VERSION ""

CM_ "AUTOGENERATED FILE, DO NOT EDIT";

CM_ "tesla_radar_continental.dbc starts here";

NS_ :

BS_:

BU_:  Autopilot Radar Diag

BO_ 1025 RadarStatus: 8 Radar
   SG_ carparkDetected : 29|1@1+ (1,0) [0|1] "" Autopilot
   SG_ decreaseBlockage : 25|1@1+ (1,0) [0|1] "" Autopilot
   SG_ horizontMisalignment : 8|12@1+ (0.00012207,-0.25) [-0.25|0.249878] "rad" Autopilot
   SG_ increaseBlockage : 24|1@1+ (1,0) [0|1] "" Autopilot
   SG_ lowPowerMode : 20|2@1+ (1,0) [0|3] "" Autopilot
   SG_ powerOnSelfTest : 22|1@1+ (1,0) [0|1] "" Autopilot
   SG_ sensorBlocked : 26|1@1+ (1,0) [0|1] "" Autopilot
   SG_ sensorInfoConsistBit : 30|1@1+ (1,0) [0|1] "" Autopilot
   SG_ sensorReplace : 31|1@1+ (1,0) [0|1] "" Autopilot
   SG_ shortTermUnavailable : 23|1@1+ (1,0) [0|1] "" Autopilot
   SG_ tunnelDetected : 28|1@1+ (1,0) [0|1] "" Autopilot
   SG_ vehDynamicsError : 27|1@1+ (1,0) [0|1] "" Autopilot
   SG_ verticalMisalignment : 0|8@1+ (0.00195313,-0.25) [-0.25|0.248047] "rad" Autopilot

BO_ 1617 Radar_udsResponse: 8 Radar
   SG_ Radar_udsResponseData : 7|64@0+ (1,0) [0|1.84467e+19] "" Diag

BO_ 1601 UDS_radcRequest: 8 Diag
   SG_ UDS_radcRequestData : 7|64@0+ (1,0) [0|1.84467e+19] "" Radar

BO_ 1040 RadarPoint0_A: 8 Radar
 SG_ LongDist : 0|12@1+ (0.0625,0) [0|255.9] "meters"  Autopilot
 SG_ LongSpeed : 12|12@1+ (0.0625,-128) [-128|128] "meters/sec"  Autopilot
 SG_ LatDist : 24|11@1+ (0.125,-128) [-128|128] "meters"  Autopilot
 SG_ ProbExist : 35|5@1+ (3.125,0) [0|96.875] "%"  Autopilot
 SG_ LongAccel : 40|10@1+ (0.03125,-16) [-16|16] "meters/sec/sec"  Autopilot
 SG_ ProbObstacle : 50|5@1+ (3.125,0) [0|96.875] "%"  Autopilot
 SG_ Valid : 55|1@1+ (1,0) [0|1] ""  Autopilot
 SG_ ProbNonObstacle : 56|5@1+ (3.125,0) [0|96.875] "%"  Autopilot
 SG_ Meas : 61|1@1+ (1,0) [0|1] ""  Autopilot
 SG_ Tracked : 62|1@1+ (1,0) [0|1] ""  Autopilot
 SG_ Index : 63|1@1+ (1,0) [0|1] ""  Autopilot

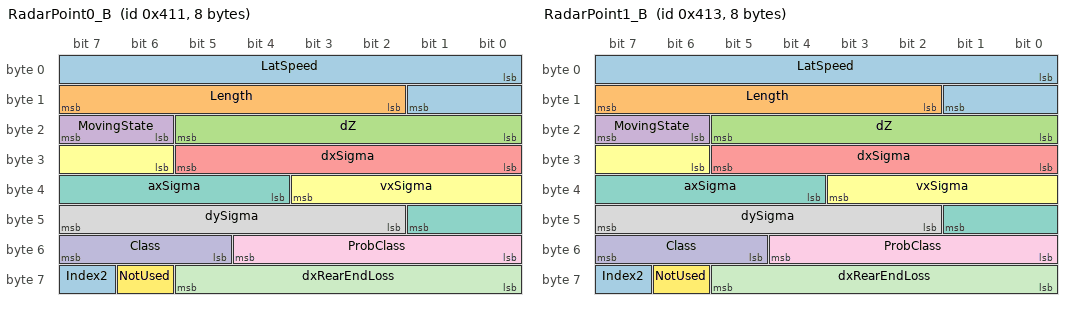
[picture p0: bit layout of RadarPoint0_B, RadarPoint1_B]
BO_ 1041 RadarPoint0_B: 8 Radar
 SG_ LatSpeed : 0|10@1+ (0.125,-64) [-64|64] "meters/sec"  Autopilot
 SG_ Length : 10|6@1+ (0.125,0) [0|7.875] "m"  Autopilot
 SG_ dZ : 16|6@1+ (0.25,-5) [-5|10.75] "m"  Autopilot
 SG_ MovingState : 22|2@1+ (1,0) [0|3] ""  Autopilot
 SG_ dxSigma : 24|6@1+ (1,0) [0|63] ""  Autopilot
 SG_ vxSigma : 30|6@1+ (1,0) [0|63] ""  Autopilot
 SG_ axSigma : 36|6@1+ (1,0) [0|63] ""  Autopilot
 SG_ dySigma : 42|6@1+ (1,0) [0|63] ""  Autopilot
 SG_ ProbClass : 48|5@1+ (3.125,0) [0|96.875] "%"  Autopilot
 SG_ Class : 53|3@1+ (1,0) [0|7] ""  Autopilot
 SG_ dxRearEndLoss : 56|6@1+ (1,0) [0|63] ""  Autopilot
 SG_ NotUsed : 62|1@1+ (1,0) [0|1] ""  Autopilot
 SG_ Index2 : 63|1@1+ (1,0) [0|1] ""  Autopilot

BO_ 1042 RadarPoint1_A: 8 Radar
 SG_ LongDist : 0|12@1+ (0.0625,0) [0|255.9] "meters"  Autopilot
 SG_ LongSpeed : 12|12@1+ (0.0625,-128) [-128|128] "meters/sec"  Autopilot
 SG_ LatDist : 24|11@1+ (0.125,-128) [-128|128] "meters"  Autopilot
 SG_ ProbExist : 35|5@1+ (3.125,0) [0|96.875] "%"  Autopilot
 SG_ LongAccel : 40|10@1+ (0.03125,-16) [-16|16] "meters/sec/sec"  Autopilot
 SG_ ProbObstacle : 50|5@1+ (3.125,0) [0|96.875] "%"  Autopilot
 SG_ Valid : 55|1@1+ (1,0) [0|1] ""  Autopilot
 SG_ ProbNonObstacle : 56|5@1+ (3.125,0) [0|96.875] "%"  Autopilot
 SG_ Meas : 61|1@1+ (1,0) [0|1] ""  Autopilot
 SG_ Tracked : 62|1@1+ (1,0) [0|1] ""  Autopilot
 SG_ Index : 63|1@1+ (1,0) [0|1] ""  Autopilot

BO_ 1043 RadarPoint1_B: 8 Radar
 SG_ LatSpeed : 0|10@1+ (0.125,-64) [-64|64] "meters/sec"  Autopilot
 SG_ Length : 10|6@1+ (0.125,0) [0|7.875] "m"  Autopilot
 SG_ dZ : 16|6@1+ (0.25,-5) [-5|10.75] "m"  Autopilot
 SG_ MovingState : 22|2@1+ (1,0) [0|3] ""  Autopilot
 SG_ dxSigma : 24|6@1+ (1,0) [0|63] ""  Autopilot
 SG_ vxSigma : 30|6@1+ (1,0) [0|63] ""  Autopilot
 SG_ axSigma : 36|6@1+ (1,0) [0|63] ""  Autopilot
 SG_ dySigma : 42|6@1+ (1,0) [0|63] ""  Autopilot
 SG_ ProbClass : 48|5@1+ (3.125,0) [0|96.875] "%"  Autopilot
 SG_ Class : 53|3@1+ (1,0) [0|7] ""  Autopilot
 SG_ dxRearEndLoss : 56|6@1+ (1,0) [0|63] ""  Autopilot
 SG_ NotUsed : 62|1@1+ (1,0) [0|1] ""  Autopilot
 SG_ Index2 : 63|1@1+ (1,0) [0|1] ""  Autopilot

BO_ 1044 RadarPoint2_A: 8 Radar
 SG_ LongDist : 0|12@1+ (0.0625,0) [0|255.9] "meters"  Autopilot
 SG_ LongSpeed : 12|12@1+ (0.0625,-128) [-128|128] "meters/sec"  Autopilot
 SG_ LatDist : 24|11@1+ (0.125,-128) [-128|128] "meters"  Autopilot
 SG_ ProbExist : 35|5@1+ (3.125,0) [0|96.875] "%"  Autopilot
 SG_ LongAccel : 40|10@1+ (0.03125,-16) [-16|16] "meters/sec/sec"  Autopilot
 SG_ ProbObstacle : 50|5@1+ (3.125,0) [0|96.875] "%"  Autopilot
 SG_ Valid : 55|1@1+ (1,0) [0|1] ""  Autopilot
 SG_ ProbNonObstacle : 56|5@1+ (3.125,0) [0|96.875] "%"  Autopilot
 SG_ Meas : 61|1@1+ (1,0) [0|1] ""  Autopilot
 SG_ Tracked : 62|1@1+ (1,0) [0|1] ""  Autopilot
 SG_ Index : 63|1@1+ (1,0) [0|1] ""  Autopilot

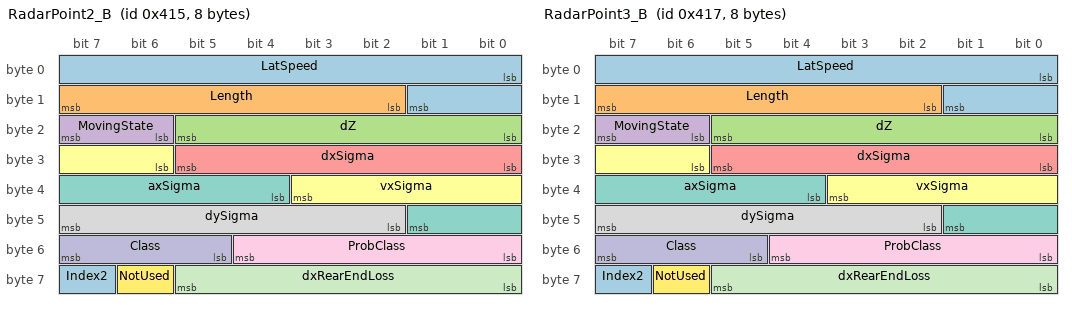
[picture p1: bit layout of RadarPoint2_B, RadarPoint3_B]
BO_ 1045 RadarPoint2_B: 8 Radar
 SG_ LatSpeed : 0|10@1+ (0.125,-64) [-64|64] "meters/sec"  Autopilot
 SG_ Length : 10|6@1+ (0.125,0) [0|7.875] "m"  Autopilot
 SG_ dZ : 16|6@1+ (0.25,-5) [-5|10.75] "m"  Autopilot
 SG_ MovingState : 22|2@1+ (1,0) [0|3] ""  Autopilot
 SG_ dxSigma : 24|6@1+ (1,0) [0|63] ""  Autopilot
 SG_ vxSigma : 30|6@1+ (1,0) [0|63] ""  Autopilot
 SG_ axSigma : 36|6@1+ (1,0) [0|63] ""  Autopilot
 SG_ dySigma : 42|6@1+ (1,0) [0|63] ""  Autopilot
 SG_ ProbClass : 48|5@1+ (3.125,0) [0|96.875] "%"  Autopilot
 SG_ Class : 53|3@1+ (1,0) [0|7] ""  Autopilot
 SG_ dxRearEndLoss : 56|6@1+ (1,0) [0|63] ""  Autopilot
 SG_ NotUsed : 62|1@1+ (1,0) [0|1] ""  Autopilot
 SG_ Index2 : 63|1@1+ (1,0) [0|1] ""  Autopilot

BO_ 1046 RadarPoint3_A: 8 Radar
 SG_ LongDist : 0|12@1+ (0.0625,0) [0|255.9] "meters"  Autopilot
 SG_ LongSpeed : 12|12@1+ (0.0625,-128) [-128|128] "meters/sec"  Autopilot
 SG_ LatDist : 24|11@1+ (0.125,-128) [-128|128] "meters"  Autopilot
 SG_ ProbExist : 35|5@1+ (3.125,0) [0|96.875] "%"  Autopilot
 SG_ LongAccel : 40|10@1+ (0.03125,-16) [-16|16] "meters/sec/sec"  Autopilot
 SG_ ProbObstacle : 50|5@1+ (3.125,0) [0|96.875] "%"  Autopilot
 SG_ Valid : 55|1@1+ (1,0) [0|1] ""  Autopilot
 SG_ ProbNonObstacle : 56|5@1+ (3.125,0) [0|96.875] "%"  Autopilot
 SG_ Meas : 61|1@1+ (1,0) [0|1] ""  Autopilot
 SG_ Tracked : 62|1@1+ (1,0) [0|1] ""  Autopilot
 SG_ Index : 63|1@1+ (1,0) [0|1] ""  Autopilot

BO_ 1047 RadarPoint3_B: 8 Radar
 SG_ LatSpeed : 0|10@1+ (0.125,-64) [-64|64] "meters/sec"  Autopilot
 SG_ Length : 10|6@1+ (0.125,0) [0|7.875] "m"  Autopilot
 SG_ dZ : 16|6@1+ (0.25,-5) [-5|10.75] "m"  Autopilot
 SG_ MovingState : 22|2@1+ (1,0) [0|3] ""  Autopilot
 SG_ dxSigma : 24|6@1+ (1,0) [0|63] ""  Autopilot
 SG_ vxSigma : 30|6@1+ (1,0) [0|63] ""  Autopilot
 SG_ axSigma : 36|6@1+ (1,0) [0|63] ""  Autopilot
 SG_ dySigma : 42|6@1+ (1,0) [0|63] ""  Autopilot
 SG_ ProbClass : 48|5@1+ (3.125,0) [0|96.875] "%"  Autopilot
 SG_ Class : 53|3@1+ (1,0) [0|7] ""  Autopilot
 SG_ dxRearEndLoss : 56|6@1+ (1,0) [0|63] ""  Autopilot
 SG_ NotUsed : 62|1@1+ (1,0) [0|1] ""  Autopilot
 SG_ Index2 : 63|1@1+ (1,0) [0|1] ""  Autopilot

BO_ 1048 RadarPoint4_A: 8 Radar
 SG_ LongDist : 0|12@1+ (0.0625,0) [0|255.9] "meters"  Autopilot
 SG_ LongSpeed : 12|12@1+ (0.0625,-128) [-128|128] "meters/sec"  Autopilot
 SG_ LatDist : 24|11@1+ (0.125,-128) [-128|128] "meters"  Autopilot
 SG_ ProbExist : 35|5@1+ (3.125,0) [0|96.875] "%"  Autopilot
 SG_ LongAccel : 40|10@1+ (0.03125,-16) [-16|16] "meters/sec/sec"  Autopilot
 SG_ ProbObstacle : 50|5@1+ (3.125,0) [0|96.875] "%"  Autopilot
 SG_ Valid : 55|1@1+ (1,0) [0|1] ""  Autopilot
 SG_ ProbNonObstacle : 56|5@1+ (3.125,0) [0|96.875] "%"  Autopilot
 SG_ Meas : 61|1@1+ (1,0) [0|1] ""  Autopilot
 SG_ Tracked : 62|1@1+ (1,0) [0|1] ""  Autopilot
 SG_ Index : 63|1@1+ (1,0) [0|1] ""  Autopilot

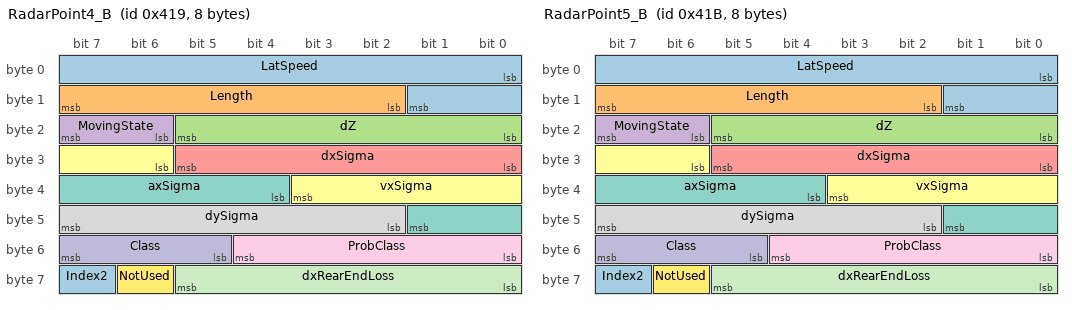
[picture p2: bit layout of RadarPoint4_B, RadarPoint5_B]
BO_ 1049 RadarPoint4_B: 8 Radar
 SG_ LatSpeed : 0|10@1+ (0.125,-64) [-64|64] "meters/sec"  Autopilot
 SG_ Length : 10|6@1+ (0.125,0) [0|7.875] "m"  Autopilot
 SG_ dZ : 16|6@1+ (0.25,-5) [-5|10.75] "m"  Autopilot
 SG_ MovingState : 22|2@1+ (1,0) [0|3] ""  Autopilot
 SG_ dxSigma : 24|6@1+ (1,0) [0|63] ""  Autopilot
 SG_ vxSigma : 30|6@1+ (1,0) [0|63] ""  Autopilot
 SG_ axSigma : 36|6@1+ (1,0) [0|63] ""  Autopilot
 SG_ dySigma : 42|6@1+ (1,0) [0|63] ""  Autopilot
 SG_ ProbClass : 48|5@1+ (3.125,0) [0|96.875] "%"  Autopilot
 SG_ Class : 53|3@1+ (1,0) [0|7] ""  Autopilot
 SG_ dxRearEndLoss : 56|6@1+ (1,0) [0|63] ""  Autopilot
 SG_ NotUsed : 62|1@1+ (1,0) [0|1] ""  Autopilot
 SG_ Index2 : 63|1@1+ (1,0) [0|1] ""  Autopilot

BO_ 1050 RadarPoint5_A: 8 Radar
 SG_ LongDist : 0|12@1+ (0.0625,0) [0|255.9] "meters"  Autopilot
 SG_ LongSpeed : 12|12@1+ (0.0625,-128) [-128|128] "meters/sec"  Autopilot
 SG_ LatDist : 24|11@1+ (0.125,-128) [-128|128] "meters"  Autopilot
 SG_ ProbExist : 35|5@1+ (3.125,0) [0|96.875] "%"  Autopilot
 SG_ LongAccel : 40|10@1+ (0.03125,-16) [-16|16] "meters/sec/sec"  Autopilot
 SG_ ProbObstacle : 50|5@1+ (3.125,0) [0|96.875] "%"  Autopilot
 SG_ Valid : 55|1@1+ (1,0) [0|1] ""  Autopilot
 SG_ ProbNonObstacle : 56|5@1+ (3.125,0) [0|96.875] "%"  Autopilot
 SG_ Meas : 61|1@1+ (1,0) [0|1] ""  Autopilot
 SG_ Tracked : 62|1@1+ (1,0) [0|1] ""  Autopilot
 SG_ Index : 63|1@1+ (1,0) [0|1] ""  Autopilot

BO_ 1051 RadarPoint5_B: 8 Radar
 SG_ LatSpeed : 0|10@1+ (0.125,-64) [-64|64] "meters/sec"  Autopilot
 SG_ Length : 10|6@1+ (0.125,0) [0|7.875] "m"  Autopilot
 SG_ dZ : 16|6@1+ (0.25,-5) [-5|10.75] "m"  Autopilot
 SG_ MovingState : 22|2@1+ (1,0) [0|3] ""  Autopilot
 SG_ dxSigma : 24|6@1+ (1,0) [0|63] ""  Autopilot
 SG_ vxSigma : 30|6@1+ (1,0) [0|63] ""  Autopilot
 SG_ axSigma : 36|6@1+ (1,0) [0|63] ""  Autopilot
 SG_ dySigma : 42|6@1+ (1,0) [0|63] ""  Autopilot
 SG_ ProbClass : 48|5@1+ (3.125,0) [0|96.875] "%"  Autopilot
 SG_ Class : 53|3@1+ (1,0) [0|7] ""  Autopilot
 SG_ dxRearEndLoss : 56|6@1+ (1,0) [0|63] ""  Autopilot
 SG_ NotUsed : 62|1@1+ (1,0) [0|1] ""  Autopilot
 SG_ Index2 : 63|1@1+ (1,0) [0|1] ""  Autopilot

BO_ 1052 RadarPoint6_A: 8 Radar
 SG_ LongDist : 0|12@1+ (0.0625,0) [0|255.9] "meters"  Autopilot
 SG_ LongSpeed : 12|12@1+ (0.0625,-128) [-128|128] "meters/sec"  Autopilot
 SG_ LatDist : 24|11@1+ (0.125,-128) [-128|128] "meters"  Autopilot
 SG_ ProbExist : 35|5@1+ (3.125,0) [0|96.875] "%"  Autopilot
 SG_ LongAccel : 40|10@1+ (0.03125,-16) [-16|16] "meters/sec/sec"  Autopilot
 SG_ ProbObstacle : 50|5@1+ (3.125,0) [0|96.875] "%"  Autopilot
 SG_ Valid : 55|1@1+ (1,0) [0|1] ""  Autopilot
 SG_ ProbNonObstacle : 56|5@1+ (3.125,0) [0|96.875] "%"  Autopilot
 SG_ Meas : 61|1@1+ (1,0) [0|1] ""  Autopilot
 SG_ Tracked : 62|1@1+ (1,0) [0|1] ""  Autopilot
 SG_ Index : 63|1@1+ (1,0) [0|1] ""  Autopilot

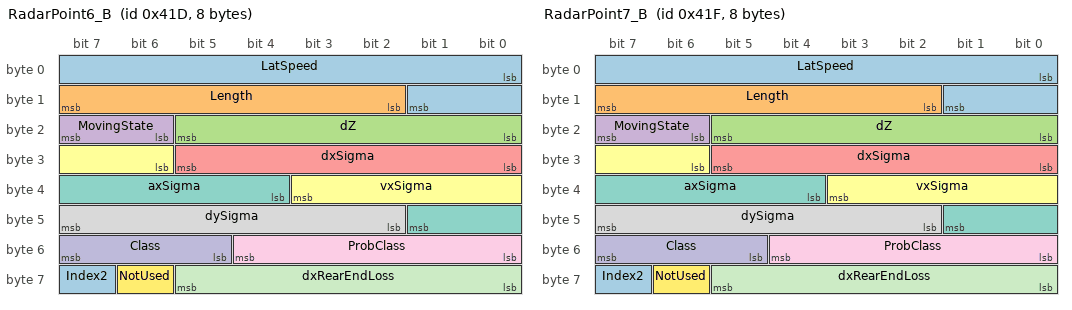
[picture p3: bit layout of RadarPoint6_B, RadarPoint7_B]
BO_ 1053 RadarPoint6_B: 8 Radar
 SG_ LatSpeed : 0|10@1+ (0.125,-64) [-64|64] "meters/sec"  Autopilot
 SG_ Length : 10|6@1+ (0.125,0) [0|7.875] "m"  Autopilot
 SG_ dZ : 16|6@1+ (0.25,-5) [-5|10.75] "m"  Autopilot
 SG_ MovingState : 22|2@1+ (1,0) [0|3] ""  Autopilot
 SG_ dxSigma : 24|6@1+ (1,0) [0|63] ""  Autopilot
 SG_ vxSigma : 30|6@1+ (1,0) [0|63] ""  Autopilot
 SG_ axSigma : 36|6@1+ (1,0) [0|63] ""  Autopilot
 SG_ dySigma : 42|6@1+ (1,0) [0|63] ""  Autopilot
 SG_ ProbClass : 48|5@1+ (3.125,0) [0|96.875] "%"  Autopilot
 SG_ Class : 53|3@1+ (1,0) [0|7] ""  Autopilot
 SG_ dxRearEndLoss : 56|6@1+ (1,0) [0|63] ""  Autopilot
 SG_ NotUsed : 62|1@1+ (1,0) [0|1] ""  Autopilot
 SG_ Index2 : 63|1@1+ (1,0) [0|1] ""  Autopilot

BO_ 1054 RadarPoint7_A: 8 Radar
 SG_ LongDist : 0|12@1+ (0.0625,0) [0|255.9] "meters"  Autopilot
 SG_ LongSpeed : 12|12@1+ (0.0625,-128) [-128|128] "meters/sec"  Autopilot
 SG_ LatDist : 24|11@1+ (0.125,-128) [-128|128] "meters"  Autopilot
 SG_ ProbExist : 35|5@1+ (3.125,0) [0|96.875] "%"  Autopilot
 SG_ LongAccel : 40|10@1+ (0.03125,-16) [-16|16] "meters/sec/sec"  Autopilot
 SG_ ProbObstacle : 50|5@1+ (3.125,0) [0|96.875] "%"  Autopilot
 SG_ Valid : 55|1@1+ (1,0) [0|1] ""  Autopilot
 SG_ ProbNonObstacle : 56|5@1+ (3.125,0) [0|96.875] "%"  Autopilot
 SG_ Meas : 61|1@1+ (1,0) [0|1] ""  Autopilot
 SG_ Tracked : 62|1@1+ (1,0) [0|1] ""  Autopilot
 SG_ Index : 63|1@1+ (1,0) [0|1] ""  Autopilot

BO_ 1055 RadarPoint7_B: 8 Radar
 SG_ LatSpeed : 0|10@1+ (0.125,-64) [-64|64] "meters/sec"  Autopilot
 SG_ Length : 10|6@1+ (0.125,0) [0|7.875] "m"  Autopilot
 SG_ dZ : 16|6@1+ (0.25,-5) [-5|10.75] "m"  Autopilot
 SG_ MovingState : 22|2@1+ (1,0) [0|3] ""  Autopilot
 SG_ dxSigma : 24|6@1+ (1,0) [0|63] ""  Autopilot
 SG_ vxSigma : 30|6@1+ (1,0) [0|63] ""  Autopilot
 SG_ axSigma : 36|6@1+ (1,0) [0|63] ""  Autopilot
 SG_ dySigma : 42|6@1+ (1,0) [0|63] ""  Autopilot
 SG_ ProbClass : 48|5@1+ (3.125,0) [0|96.875] "%"  Autopilot
 SG_ Class : 53|3@1+ (1,0) [0|7] ""  Autopilot
 SG_ dxRearEndLoss : 56|6@1+ (1,0) [0|63] ""  Autopilot
 SG_ NotUsed : 62|1@1+ (1,0) [0|1] ""  Autopilot
 SG_ Index2 : 63|1@1+ (1,0) [0|1] ""  Autopilot

BO_ 1056 RadarPoint8_A: 8 Radar
 SG_ LongDist : 0|12@1+ (0.0625,0) [0|255.9] "meters"  Autopilot
 SG_ LongSpeed : 12|12@1+ (0.0625,-128) [-128|128] "meters/sec"  Autopilot
 SG_ LatDist : 24|11@1+ (0.125,-128) [-128|128] "meters"  Autopilot
 SG_ ProbExist : 35|5@1+ (3.125,0) [0|96.875] "%"  Autopilot
 SG_ LongAccel : 40|10@1+ (0.03125,-16) [-16|16] "meters/sec/sec"  Autopilot
 SG_ ProbObstacle : 50|5@1+ (3.125,0) [0|96.875] "%"  Autopilot
 SG_ Valid : 55|1@1+ (1,0) [0|1] ""  Autopilot
 SG_ ProbNonObstacle : 56|5@1+ (3.125,0) [0|96.875] "%"  Autopilot
 SG_ Meas : 61|1@1+ (1,0) [0|1] ""  Autopilot
 SG_ Tracked : 62|1@1+ (1,0) [0|1] ""  Autopilot
 SG_ Index : 63|1@1+ (1,0) [0|1] ""  Autopilot

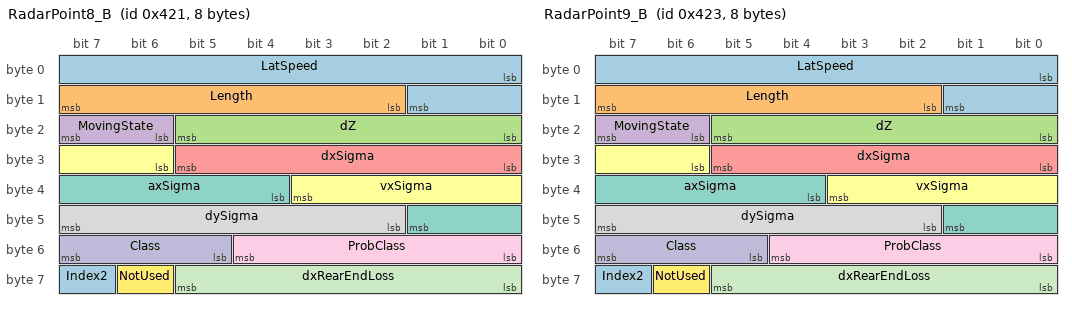
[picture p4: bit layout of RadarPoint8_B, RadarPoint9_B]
BO_ 1057 RadarPoint8_B: 8 Radar
 SG_ LatSpeed : 0|10@1+ (0.125,-64) [-64|64] "meters/sec"  Autopilot
 SG_ Length : 10|6@1+ (0.125,0) [0|7.875] "m"  Autopilot
 SG_ dZ : 16|6@1+ (0.25,-5) [-5|10.75] "m"  Autopilot
 SG_ MovingState : 22|2@1+ (1,0) [0|3] ""  Autopilot
 SG_ dxSigma : 24|6@1+ (1,0) [0|63] ""  Autopilot
 SG_ vxSigma : 30|6@1+ (1,0) [0|63] ""  Autopilot
 SG_ axSigma : 36|6@1+ (1,0) [0|63] ""  Autopilot
 SG_ dySigma : 42|6@1+ (1,0) [0|63] ""  Autopilot
 SG_ ProbClass : 48|5@1+ (3.125,0) [0|96.875] "%"  Autopilot
 SG_ Class : 53|3@1+ (1,0) [0|7] ""  Autopilot
 SG_ dxRearEndLoss : 56|6@1+ (1,0) [0|63] ""  Autopilot
 SG_ NotUsed : 62|1@1+ (1,0) [0|1] ""  Autopilot
 SG_ Index2 : 63|1@1+ (1,0) [0|1] ""  Autopilot

BO_ 1058 RadarPoint9_A: 8 Radar
 SG_ LongDist : 0|12@1+ (0.0625,0) [0|255.9] "meters"  Autopilot
 SG_ LongSpeed : 12|12@1+ (0.0625,-128) [-128|128] "meters/sec"  Autopilot
 SG_ LatDist : 24|11@1+ (0.125,-128) [-128|128] "meters"  Autopilot
 SG_ ProbExist : 35|5@1+ (3.125,0) [0|96.875] "%"  Autopilot
 SG_ LongAccel : 40|10@1+ (0.03125,-16) [-16|16] "meters/sec/sec"  Autopilot
 SG_ ProbObstacle : 50|5@1+ (3.125,0) [0|96.875] "%"  Autopilot
 SG_ Valid : 55|1@1+ (1,0) [0|1] ""  Autopilot
 SG_ ProbNonObstacle : 56|5@1+ (3.125,0) [0|96.875] "%"  Autopilot
 SG_ Meas : 61|1@1+ (1,0) [0|1] ""  Autopilot
 SG_ Tracked : 62|1@1+ (1,0) [0|1] ""  Autopilot
 SG_ Index : 63|1@1+ (1,0) [0|1] ""  Autopilot

BO_ 1059 RadarPoint9_B: 8 Radar
 SG_ LatSpeed : 0|10@1+ (0.125,-64) [-64|64] "meters/sec"  Autopilot
 SG_ Length : 10|6@1+ (0.125,0) [0|7.875] "m"  Autopilot
 SG_ dZ : 16|6@1+ (0.25,-5) [-5|10.75] "m"  Autopilot
 SG_ MovingState : 22|2@1+ (1,0) [0|3] ""  Autopilot
 SG_ dxSigma : 24|6@1+ (1,0) [0|63] ""  Autopilot
 SG_ vxSigma : 30|6@1+ (1,0) [0|63] ""  Autopilot
 SG_ axSigma : 36|6@1+ (1,0) [0|63] ""  Autopilot
 SG_ dySigma : 42|6@1+ (1,0) [0|63] ""  Autopilot
 SG_ ProbClass : 48|5@1+ (3.125,0) [0|96.875] "%"  Autopilot
 SG_ Class : 53|3@1+ (1,0) [0|7] ""  Autopilot
 SG_ dxRearEndLoss : 56|6@1+ (1,0) [0|63] ""  Autopilot
 SG_ NotUsed : 62|1@1+ (1,0) [0|1] ""  Autopilot
 SG_ Index2 : 63|1@1+ (1,0) [0|1] ""  Autopilot

BO_ 1060 RadarPoint10_A: 8 Radar
 SG_ LongDist : 0|12@1+ (0.0625,0) [0|255.9] "meters"  Autopilot
 SG_ LongSpeed : 12|12@1+ (0.0625,-128) [-128|128] "meters/sec"  Autopilot
 SG_ LatDist : 24|11@1+ (0.125,-128) [-128|128] "meters"  Autopilot
 SG_ ProbExist : 35|5@1+ (3.125,0) [0|96.875] "%"  Autopilot
 SG_ LongAccel : 40|10@1+ (0.03125,-16) [-16|16] "meters/sec/sec"  Autopilot
 SG_ ProbObstacle : 50|5@1+ (3.125,0) [0|96.875] "%"  Autopilot
 SG_ Valid : 55|1@1+ (1,0) [0|1] ""  Autopilot
 SG_ ProbNonObstacle : 56|5@1+ (3.125,0) [0|96.875] "%"  Autopilot
 SG_ Meas : 61|1@1+ (1,0) [0|1] ""  Autopilot
 SG_ Tracked : 62|1@1+ (1,0) [0|1] ""  Autopilot
 SG_ Index : 63|1@1+ (1,0) [0|1] ""  Autopilot

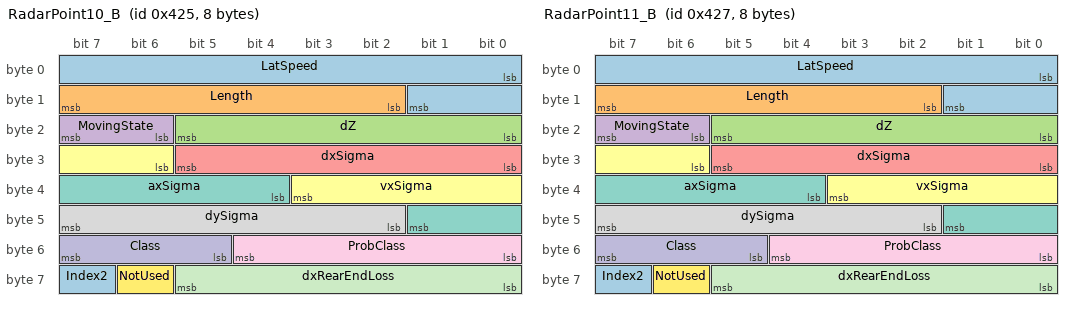
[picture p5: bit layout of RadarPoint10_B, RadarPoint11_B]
BO_ 1061 RadarPoint10_B: 8 Radar
 SG_ LatSpeed : 0|10@1+ (0.125,-64) [-64|64] "meters/sec"  Autopilot
 SG_ Length : 10|6@1+ (0.125,0) [0|7.875] "m"  Autopilot
 SG_ dZ : 16|6@1+ (0.25,-5) [-5|10.75] "m"  Autopilot
 SG_ MovingState : 22|2@1+ (1,0) [0|3] ""  Autopilot
 SG_ dxSigma : 24|6@1+ (1,0) [0|63] ""  Autopilot
 SG_ vxSigma : 30|6@1+ (1,0) [0|63] ""  Autopilot
 SG_ axSigma : 36|6@1+ (1,0) [0|63] ""  Autopilot
 SG_ dySigma : 42|6@1+ (1,0) [0|63] ""  Autopilot
 SG_ ProbClass : 48|5@1+ (3.125,0) [0|96.875] "%"  Autopilot
 SG_ Class : 53|3@1+ (1,0) [0|7] ""  Autopilot
 SG_ dxRearEndLoss : 56|6@1+ (1,0) [0|63] ""  Autopilot
 SG_ NotUsed : 62|1@1+ (1,0) [0|1] ""  Autopilot
 SG_ Index2 : 63|1@1+ (1,0) [0|1] ""  Autopilot

BO_ 1062 RadarPoint11_A: 8 Radar
 SG_ LongDist : 0|12@1+ (0.0625,0) [0|255.9] "meters"  Autopilot
 SG_ LongSpeed : 12|12@1+ (0.0625,-128) [-128|128] "meters/sec"  Autopilot
 SG_ LatDist : 24|11@1+ (0.125,-128) [-128|128] "meters"  Autopilot
 SG_ ProbExist : 35|5@1+ (3.125,0) [0|96.875] "%"  Autopilot
 SG_ LongAccel : 40|10@1+ (0.03125,-16) [-16|16] "meters/sec/sec"  Autopilot
 SG_ ProbObstacle : 50|5@1+ (3.125,0) [0|96.875] "%"  Autopilot
 SG_ Valid : 55|1@1+ (1,0) [0|1] ""  Autopilot
 SG_ ProbNonObstacle : 56|5@1+ (3.125,0) [0|96.875] "%"  Autopilot
 SG_ Meas : 61|1@1+ (1,0) [0|1] ""  Autopilot
 SG_ Tracked : 62|1@1+ (1,0) [0|1] ""  Autopilot
 SG_ Index : 63|1@1+ (1,0) [0|1] ""  Autopilot

BO_ 1063 RadarPoint11_B: 8 Radar
 SG_ LatSpeed : 0|10@1+ (0.125,-64) [-64|64] "meters/sec"  Autopilot
 SG_ Length : 10|6@1+ (0.125,0) [0|7.875] "m"  Autopilot
 SG_ dZ : 16|6@1+ (0.25,-5) [-5|10.75] "m"  Autopilot
 SG_ MovingState : 22|2@1+ (1,0) [0|3] ""  Autopilot
 SG_ dxSigma : 24|6@1+ (1,0) [0|63] ""  Autopilot
 SG_ vxSigma : 30|6@1+ (1,0) [0|63] ""  Autopilot
 SG_ axSigma : 36|6@1+ (1,0) [0|63] ""  Autopilot
 SG_ dySigma : 42|6@1+ (1,0) [0|63] ""  Autopilot
 SG_ ProbClass : 48|5@1+ (3.125,0) [0|96.875] "%"  Autopilot
 SG_ Class : 53|3@1+ (1,0) [0|7] ""  Autopilot
 SG_ dxRearEndLoss : 56|6@1+ (1,0) [0|63] ""  Autopilot
 SG_ NotUsed : 62|1@1+ (1,0) [0|1] ""  Autopilot
 SG_ Index2 : 63|1@1+ (1,0) [0|1] ""  Autopilot

BO_ 1064 RadarPoint12_A: 8 Radar
 SG_ LongDist : 0|12@1+ (0.0625,0) [0|255.9] "meters"  Autopilot
 SG_ LongSpeed : 12|12@1+ (0.0625,-128) [-128|128] "meters/sec"  Autopilot
 SG_ LatDist : 24|11@1+ (0.125,-128) [-128|128] "meters"  Autopilot
 SG_ ProbExist : 35|5@1+ (3.125,0) [0|96.875] "%"  Autopilot
 SG_ LongAccel : 40|10@1+ (0.03125,-16) [-16|16] "meters/sec/sec"  Autopilot
 SG_ ProbObstacle : 50|5@1+ (3.125,0) [0|96.875] "%"  Autopilot
 SG_ Valid : 55|1@1+ (1,0) [0|1] ""  Autopilot
 SG_ ProbNonObstacle : 56|5@1+ (3.125,0) [0|96.875] "%"  Autopilot
 SG_ Meas : 61|1@1+ (1,0) [0|1] ""  Autopilot
 SG_ Tracked : 62|1@1+ (1,0) [0|1] ""  Autopilot
 SG_ Index : 63|1@1+ (1,0) [0|1] ""  Autopilot

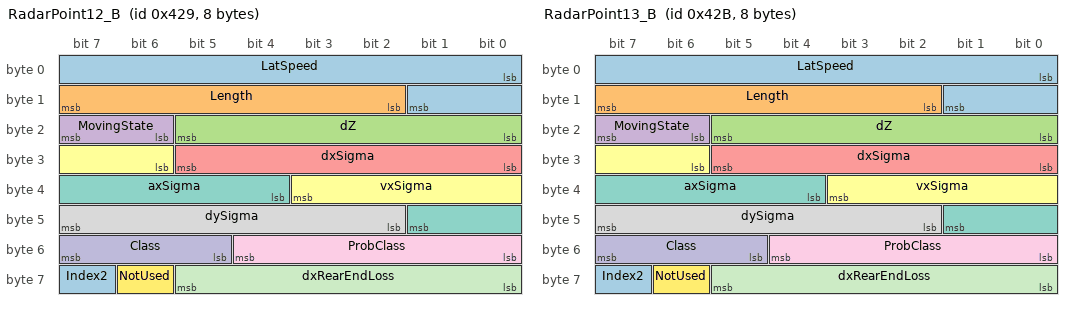
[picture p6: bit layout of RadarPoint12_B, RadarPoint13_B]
BO_ 1065 RadarPoint12_B: 8 Radar
 SG_ LatSpeed : 0|10@1+ (0.125,-64) [-64|64] "meters/sec"  Autopilot
 SG_ Length : 10|6@1+ (0.125,0) [0|7.875] "m"  Autopilot
 SG_ dZ : 16|6@1+ (0.25,-5) [-5|10.75] "m"  Autopilot
 SG_ MovingState : 22|2@1+ (1,0) [0|3] ""  Autopilot
 SG_ dxSigma : 24|6@1+ (1,0) [0|63] ""  Autopilot
 SG_ vxSigma : 30|6@1+ (1,0) [0|63] ""  Autopilot
 SG_ axSigma : 36|6@1+ (1,0) [0|63] ""  Autopilot
 SG_ dySigma : 42|6@1+ (1,0) [0|63] ""  Autopilot
 SG_ ProbClass : 48|5@1+ (3.125,0) [0|96.875] "%"  Autopilot
 SG_ Class : 53|3@1+ (1,0) [0|7] ""  Autopilot
 SG_ dxRearEndLoss : 56|6@1+ (1,0) [0|63] ""  Autopilot
 SG_ NotUsed : 62|1@1+ (1,0) [0|1] ""  Autopilot
 SG_ Index2 : 63|1@1+ (1,0) [0|1] ""  Autopilot

BO_ 1066 RadarPoint13_A: 8 Radar
 SG_ LongDist : 0|12@1+ (0.0625,0) [0|255.9] "meters"  Autopilot
 SG_ LongSpeed : 12|12@1+ (0.0625,-128) [-128|128] "meters/sec"  Autopilot
 SG_ LatDist : 24|11@1+ (0.125,-128) [-128|128] "meters"  Autopilot
 SG_ ProbExist : 35|5@1+ (3.125,0) [0|96.875] "%"  Autopilot
 SG_ LongAccel : 40|10@1+ (0.03125,-16) [-16|16] "meters/sec/sec"  Autopilot
 SG_ ProbObstacle : 50|5@1+ (3.125,0) [0|96.875] "%"  Autopilot
 SG_ Valid : 55|1@1+ (1,0) [0|1] ""  Autopilot
 SG_ ProbNonObstacle : 56|5@1+ (3.125,0) [0|96.875] "%"  Autopilot
 SG_ Meas : 61|1@1+ (1,0) [0|1] ""  Autopilot
 SG_ Tracked : 62|1@1+ (1,0) [0|1] ""  Autopilot
 SG_ Index : 63|1@1+ (1,0) [0|1] ""  Autopilot

BO_ 1067 RadarPoint13_B: 8 Radar
 SG_ LatSpeed : 0|10@1+ (0.125,-64) [-64|64] "meters/sec"  Autopilot
 SG_ Length : 10|6@1+ (0.125,0) [0|7.875] "m"  Autopilot
 SG_ dZ : 16|6@1+ (0.25,-5) [-5|10.75] "m"  Autopilot
 SG_ MovingState : 22|2@1+ (1,0) [0|3] ""  Autopilot
 SG_ dxSigma : 24|6@1+ (1,0) [0|63] ""  Autopilot
 SG_ vxSigma : 30|6@1+ (1,0) [0|63] ""  Autopilot
 SG_ axSigma : 36|6@1+ (1,0) [0|63] ""  Autopilot
 SG_ dySigma : 42|6@1+ (1,0) [0|63] ""  Autopilot
 SG_ ProbClass : 48|5@1+ (3.125,0) [0|96.875] "%"  Autopilot
 SG_ Class : 53|3@1+ (1,0) [0|7] ""  Autopilot
 SG_ dxRearEndLoss : 56|6@1+ (1,0) [0|63] ""  Autopilot
 SG_ NotUsed : 62|1@1+ (1,0) [0|1] ""  Autopilot
 SG_ Index2 : 63|1@1+ (1,0) [0|1] ""  Autopilot

BO_ 1068 RadarPoint14_A: 8 Radar
 SG_ LongDist : 0|12@1+ (0.0625,0) [0|255.9] "meters"  Autopilot
 SG_ LongSpeed : 12|12@1+ (0.0625,-128) [-128|128] "meters/sec"  Autopilot
 SG_ LatDist : 24|11@1+ (0.125,-128) [-128|128] "meters"  Autopilot
 SG_ ProbExist : 35|5@1+ (3.125,0) [0|96.875] "%"  Autopilot
 SG_ LongAccel : 40|10@1+ (0.03125,-16) [-16|16] "meters/sec/sec"  Autopilot
 SG_ ProbObstacle : 50|5@1+ (3.125,0) [0|96.875] "%"  Autopilot
 SG_ Valid : 55|1@1+ (1,0) [0|1] ""  Autopilot
 SG_ ProbNonObstacle : 56|5@1+ (3.125,0) [0|96.875] "%"  Autopilot
 SG_ Meas : 61|1@1+ (1,0) [0|1] ""  Autopilot
 SG_ Tracked : 62|1@1+ (1,0) [0|1] ""  Autopilot
 SG_ Index : 63|1@1+ (1,0) [0|1] ""  Autopilot

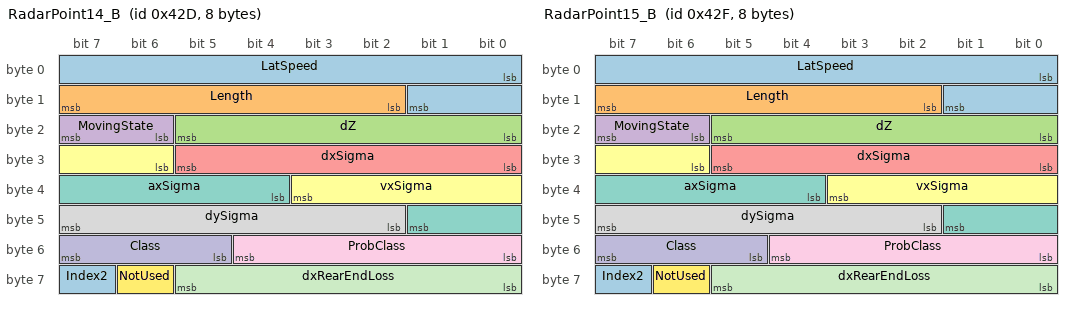
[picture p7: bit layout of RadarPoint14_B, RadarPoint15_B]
BO_ 1069 RadarPoint14_B: 8 Radar
 SG_ LatSpeed : 0|10@1+ (0.125,-64) [-64|64] "meters/sec"  Autopilot
 SG_ Length : 10|6@1+ (0.125,0) [0|7.875] "m"  Autopilot
 SG_ dZ : 16|6@1+ (0.25,-5) [-5|10.75] "m"  Autopilot
 SG_ MovingState : 22|2@1+ (1,0) [0|3] ""  Autopilot
 SG_ dxSigma : 24|6@1+ (1,0) [0|63] ""  Autopilot
 SG_ vxSigma : 30|6@1+ (1,0) [0|63] ""  Autopilot
 SG_ axSigma : 36|6@1+ (1,0) [0|63] ""  Autopilot
 SG_ dySigma : 42|6@1+ (1,0) [0|63] ""  Autopilot
 SG_ ProbClass : 48|5@1+ (3.125,0) [0|96.875] "%"  Autopilot
 SG_ Class : 53|3@1+ (1,0) [0|7] ""  Autopilot
 SG_ dxRearEndLoss : 56|6@1+ (1,0) [0|63] ""  Autopilot
 SG_ NotUsed : 62|1@1+ (1,0) [0|1] ""  Autopilot
 SG_ Index2 : 63|1@1+ (1,0) [0|1] ""  Autopilot

BO_ 1070 RadarPoint15_A: 8 Radar
 SG_ LongDist : 0|12@1+ (0.0625,0) [0|255.9] "meters"  Autopilot
 SG_ LongSpeed : 12|12@1+ (0.0625,-128) [-128|128] "meters/sec"  Autopilot
 SG_ LatDist : 24|11@1+ (0.125,-128) [-128|128] "meters"  Autopilot
 SG_ ProbExist : 35|5@1+ (3.125,0) [0|96.875] "%"  Autopilot
 SG_ LongAccel : 40|10@1+ (0.03125,-16) [-16|16] "meters/sec/sec"  Autopilot
 SG_ ProbObstacle : 50|5@1+ (3.125,0) [0|96.875] "%"  Autopilot
 SG_ Valid : 55|1@1+ (1,0) [0|1] ""  Autopilot
 SG_ ProbNonObstacle : 56|5@1+ (3.125,0) [0|96.875] "%"  Autopilot
 SG_ Meas : 61|1@1+ (1,0) [0|1] ""  Autopilot
 SG_ Tracked : 62|1@1+ (1,0) [0|1] ""  Autopilot
 SG_ Index : 63|1@1+ (1,0) [0|1] ""  Autopilot

BO_ 1071 RadarPoint15_B: 8 Radar
 SG_ LatSpeed : 0|10@1+ (0.125,-64) [-64|64] "meters/sec"  Autopilot
 SG_ Length : 10|6@1+ (0.125,0) [0|7.875] "m"  Autopilot
 SG_ dZ : 16|6@1+ (0.25,-5) [-5|10.75] "m"  Autopilot
 SG_ MovingState : 22|2@1+ (1,0) [0|3] ""  Autopilot
 SG_ dxSigma : 24|6@1+ (1,0) [0|63] ""  Autopilot
 SG_ vxSigma : 30|6@1+ (1,0) [0|63] ""  Autopilot
 SG_ axSigma : 36|6@1+ (1,0) [0|63] ""  Autopilot
 SG_ dySigma : 42|6@1+ (1,0) [0|63] ""  Autopilot
 SG_ ProbClass : 48|5@1+ (3.125,0) [0|96.875] "%"  Autopilot
 SG_ Class : 53|3@1+ (1,0) [0|7] ""  Autopilot
 SG_ dxRearEndLoss : 56|6@1+ (1,0) [0|63] ""  Autopilot
 SG_ NotUsed : 62|1@1+ (1,0) [0|1] ""  Autopilot
 SG_ Index2 : 63|1@1+ (1,0) [0|1] ""  Autopilot

BO_ 1072 RadarPoint16_A: 8 Radar
 SG_ LongDist : 0|12@1+ (0.0625,0) [0|255.9] "meters"  Autopilot
 SG_ LongSpeed : 12|12@1+ (0.0625,-128) [-128|128] "meters/sec"  Autopilot
 SG_ LatDist : 24|11@1+ (0.125,-128) [-128|128] "meters"  Autopilot
 SG_ ProbExist : 35|5@1+ (3.125,0) [0|96.875] "%"  Autopilot
 SG_ LongAccel : 40|10@1+ (0.03125,-16) [-16|16] "meters/sec/sec"  Autopilot
 SG_ ProbObstacle : 50|5@1+ (3.125,0) [0|96.875] "%"  Autopilot
 SG_ Valid : 55|1@1+ (1,0) [0|1] ""  Autopilot
 SG_ ProbNonObstacle : 56|5@1+ (3.125,0) [0|96.875] "%"  Autopilot
 SG_ Meas : 61|1@1+ (1,0) [0|1] ""  Autopilot
 SG_ Tracked : 62|1@1+ (1,0) [0|1] ""  Autopilot
 SG_ Index : 63|1@1+ (1,0) [0|1] ""  Autopilot

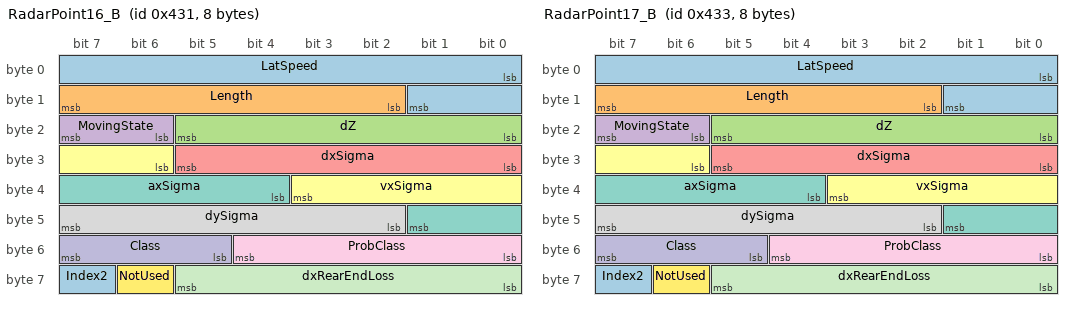
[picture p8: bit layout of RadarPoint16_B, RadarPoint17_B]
BO_ 1073 RadarPoint16_B: 8 Radar
 SG_ LatSpeed : 0|10@1+ (0.125,-64) [-64|64] "meters/sec"  Autopilot
 SG_ Length : 10|6@1+ (0.125,0) [0|7.875] "m"  Autopilot
 SG_ dZ : 16|6@1+ (0.25,-5) [-5|10.75] "m"  Autopilot
 SG_ MovingState : 22|2@1+ (1,0) [0|3] ""  Autopilot
 SG_ dxSigma : 24|6@1+ (1,0) [0|63] ""  Autopilot
 SG_ vxSigma : 30|6@1+ (1,0) [0|63] ""  Autopilot
 SG_ axSigma : 36|6@1+ (1,0) [0|63] ""  Autopilot
 SG_ dySigma : 42|6@1+ (1,0) [0|63] ""  Autopilot
 SG_ ProbClass : 48|5@1+ (3.125,0) [0|96.875] "%"  Autopilot
 SG_ Class : 53|3@1+ (1,0) [0|7] ""  Autopilot
 SG_ dxRearEndLoss : 56|6@1+ (1,0) [0|63] ""  Autopilot
 SG_ NotUsed : 62|1@1+ (1,0) [0|1] ""  Autopilot
 SG_ Index2 : 63|1@1+ (1,0) [0|1] ""  Autopilot

BO_ 1074 RadarPoint17_A: 8 Radar
 SG_ LongDist : 0|12@1+ (0.0625,0) [0|255.9] "meters"  Autopilot
 SG_ LongSpeed : 12|12@1+ (0.0625,-128) [-128|128] "meters/sec"  Autopilot
 SG_ LatDist : 24|11@1+ (0.125,-128) [-128|128] "meters"  Autopilot
 SG_ ProbExist : 35|5@1+ (3.125,0) [0|96.875] "%"  Autopilot
 SG_ LongAccel : 40|10@1+ (0.03125,-16) [-16|16] "meters/sec/sec"  Autopilot
 SG_ ProbObstacle : 50|5@1+ (3.125,0) [0|96.875] "%"  Autopilot
 SG_ Valid : 55|1@1+ (1,0) [0|1] ""  Autopilot
 SG_ ProbNonObstacle : 56|5@1+ (3.125,0) [0|96.875] "%"  Autopilot
 SG_ Meas : 61|1@1+ (1,0) [0|1] ""  Autopilot
 SG_ Tracked : 62|1@1+ (1,0) [0|1] ""  Autopilot
 SG_ Index : 63|1@1+ (1,0) [0|1] ""  Autopilot

BO_ 1075 RadarPoint17_B: 8 Radar
 SG_ LatSpeed : 0|10@1+ (0.125,-64) [-64|64] "meters/sec"  Autopilot
 SG_ Length : 10|6@1+ (0.125,0) [0|7.875] "m"  Autopilot
 SG_ dZ : 16|6@1+ (0.25,-5) [-5|10.75] "m"  Autopilot
 SG_ MovingState : 22|2@1+ (1,0) [0|3] ""  Autopilot
 SG_ dxSigma : 24|6@1+ (1,0) [0|63] ""  Autopilot
 SG_ vxSigma : 30|6@1+ (1,0) [0|63] ""  Autopilot
 SG_ axSigma : 36|6@1+ (1,0) [0|63] ""  Autopilot
 SG_ dySigma : 42|6@1+ (1,0) [0|63] ""  Autopilot
 SG_ ProbClass : 48|5@1+ (3.125,0) [0|96.875] "%"  Autopilot
 SG_ Class : 53|3@1+ (1,0) [0|7] ""  Autopilot
 SG_ dxRearEndLoss : 56|6@1+ (1,0) [0|63] ""  Autopilot
 SG_ NotUsed : 62|1@1+ (1,0) [0|1] ""  Autopilot
 SG_ Index2 : 63|1@1+ (1,0) [0|1] ""  Autopilot

BO_ 1076 RadarPoint18_A: 8 Radar
 SG_ LongDist : 0|12@1+ (0.0625,0) [0|255.9] "meters"  Autopilot
 SG_ LongSpeed : 12|12@1+ (0.0625,-128) [-128|128] "meters/sec"  Autopilot
 SG_ LatDist : 24|11@1+ (0.125,-128) [-128|128] "meters"  Autopilot
 SG_ ProbExist : 35|5@1+ (3.125,0) [0|96.875] "%"  Autopilot
 SG_ LongAccel : 40|10@1+ (0.03125,-16) [-16|16] "meters/sec/sec"  Autopilot
 SG_ ProbObstacle : 50|5@1+ (3.125,0) [0|96.875] "%"  Autopilot
 SG_ Valid : 55|1@1+ (1,0) [0|1] ""  Autopilot
 SG_ ProbNonObstacle : 56|5@1+ (3.125,0) [0|96.875] "%"  Autopilot
 SG_ Meas : 61|1@1+ (1,0) [0|1] ""  Autopilot
 SG_ Tracked : 62|1@1+ (1,0) [0|1] ""  Autopilot
 SG_ Index : 63|1@1+ (1,0) [0|1] ""  Autopilot

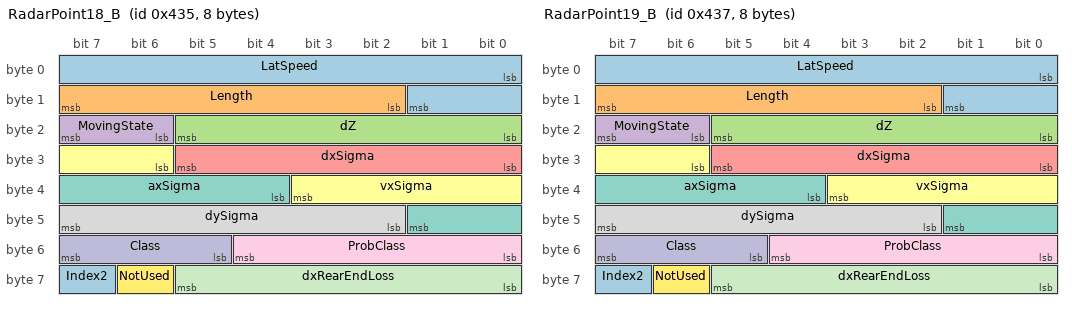
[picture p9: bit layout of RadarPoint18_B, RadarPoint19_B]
BO_ 1077 RadarPoint18_B: 8 Radar
 SG_ LatSpeed : 0|10@1+ (0.125,-64) [-64|64] "meters/sec"  Autopilot
 SG_ Length : 10|6@1+ (0.125,0) [0|7.875] "m"  Autopilot
 SG_ dZ : 16|6@1+ (0.25,-5) [-5|10.75] "m"  Autopilot
 SG_ MovingState : 22|2@1+ (1,0) [0|3] ""  Autopilot
 SG_ dxSigma : 24|6@1+ (1,0) [0|63] ""  Autopilot
 SG_ vxSigma : 30|6@1+ (1,0) [0|63] ""  Autopilot
 SG_ axSigma : 36|6@1+ (1,0) [0|63] ""  Autopilot
 SG_ dySigma : 42|6@1+ (1,0) [0|63] ""  Autopilot
 SG_ ProbClass : 48|5@1+ (3.125,0) [0|96.875] "%"  Autopilot
 SG_ Class : 53|3@1+ (1,0) [0|7] ""  Autopilot
 SG_ dxRearEndLoss : 56|6@1+ (1,0) [0|63] ""  Autopilot
 SG_ NotUsed : 62|1@1+ (1,0) [0|1] ""  Autopilot
 SG_ Index2 : 63|1@1+ (1,0) [0|1] ""  Autopilot

BO_ 1078 RadarPoint19_A: 8 Radar
 SG_ LongDist : 0|12@1+ (0.0625,0) [0|255.9] "meters"  Autopilot
 SG_ LongSpeed : 12|12@1+ (0.0625,-128) [-128|128] "meters/sec"  Autopilot
 SG_ LatDist : 24|11@1+ (0.125,-128) [-128|128] "meters"  Autopilot
 SG_ ProbExist : 35|5@1+ (3.125,0) [0|96.875] "%"  Autopilot
 SG_ LongAccel : 40|10@1+ (0.03125,-16) [-16|16] "meters/sec/sec"  Autopilot
 SG_ ProbObstacle : 50|5@1+ (3.125,0) [0|96.875] "%"  Autopilot
 SG_ Valid : 55|1@1+ (1,0) [0|1] ""  Autopilot
 SG_ ProbNonObstacle : 56|5@1+ (3.125,0) [0|96.875] "%"  Autopilot
 SG_ Meas : 61|1@1+ (1,0) [0|1] ""  Autopilot
 SG_ Tracked : 62|1@1+ (1,0) [0|1] ""  Autopilot
 SG_ Index : 63|1@1+ (1,0) [0|1] ""  Autopilot

BO_ 1079 RadarPoint19_B: 8 Radar
 SG_ LatSpeed : 0|10@1+ (0.125,-64) [-64|64] "meters/sec"  Autopilot
 SG_ Length : 10|6@1+ (0.125,0) [0|7.875] "m"  Autopilot
 SG_ dZ : 16|6@1+ (0.25,-5) [-5|10.75] "m"  Autopilot
 SG_ MovingState : 22|2@1+ (1,0) [0|3] ""  Autopilot
 SG_ dxSigma : 24|6@1+ (1,0) [0|63] ""  Autopilot
 SG_ vxSigma : 30|6@1+ (1,0) [0|63] ""  Autopilot
 SG_ axSigma : 36|6@1+ (1,0) [0|63] ""  Autopilot
 SG_ dySigma : 42|6@1+ (1,0) [0|63] ""  Autopilot
 SG_ ProbClass : 48|5@1+ (3.125,0) [0|96.875] "%"  Autopilot
 SG_ Class : 53|3@1+ (1,0) [0|7] ""  Autopilot
 SG_ dxRearEndLoss : 56|6@1+ (1,0) [0|63] ""  Autopilot
 SG_ NotUsed : 62|1@1+ (1,0) [0|1] ""  Autopilot
 SG_ Index2 : 63|1@1+ (1,0) [0|1] ""  Autopilot

BO_ 1080 RadarPoint20_A: 8 Radar
 SG_ LongDist : 0|12@1+ (0.0625,0) [0|255.9] "meters"  Autopilot
 SG_ LongSpeed : 12|12@1+ (0.0625,-128) [-128|128] "meters/sec"  Autopilot
 SG_ LatDist : 24|11@1+ (0.125,-128) [-128|128] "meters"  Autopilot
 SG_ ProbExist : 35|5@1+ (3.125,0) [0|96.875] "%"  Autopilot
 SG_ LongAccel : 40|10@1+ (0.03125,-16) [-16|16] "meters/sec/sec"  Autopilot
 SG_ ProbObstacle : 50|5@1+ (3.125,0) [0|96.875] "%"  Autopilot
 SG_ Valid : 55|1@1+ (1,0) [0|1] ""  Autopilot
 SG_ ProbNonObstacle : 56|5@1+ (3.125,0) [0|96.875] "%"  Autopilot
 SG_ Meas : 61|1@1+ (1,0) [0|1] ""  Autopilot
 SG_ Tracked : 62|1@1+ (1,0) [0|1] ""  Autopilot
 SG_ Index : 63|1@1+ (1,0) [0|1] ""  Autopilot

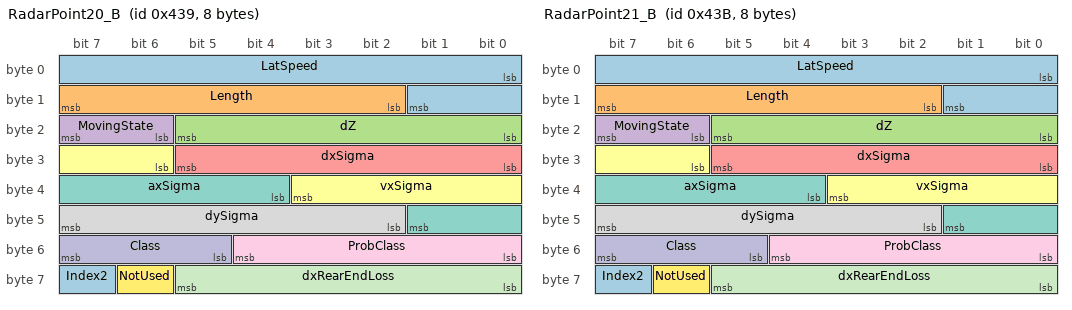
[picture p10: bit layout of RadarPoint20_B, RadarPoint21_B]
BO_ 1081 RadarPoint20_B: 8 Radar
 SG_ LatSpeed : 0|10@1+ (0.125,-64) [-64|64] "meters/sec"  Autopilot
 SG_ Length : 10|6@1+ (0.125,0) [0|7.875] "m"  Autopilot
 SG_ dZ : 16|6@1+ (0.25,-5) [-5|10.75] "m"  Autopilot
 SG_ MovingState : 22|2@1+ (1,0) [0|3] ""  Autopilot
 SG_ dxSigma : 24|6@1+ (1,0) [0|63] ""  Autopilot
 SG_ vxSigma : 30|6@1+ (1,0) [0|63] ""  Autopilot
 SG_ axSigma : 36|6@1+ (1,0) [0|63] ""  Autopilot
 SG_ dySigma : 42|6@1+ (1,0) [0|63] ""  Autopilot
 SG_ ProbClass : 48|5@1+ (3.125,0) [0|96.875] "%"  Autopilot
 SG_ Class : 53|3@1+ (1,0) [0|7] ""  Autopilot
 SG_ dxRearEndLoss : 56|6@1+ (1,0) [0|63] ""  Autopilot
 SG_ NotUsed : 62|1@1+ (1,0) [0|1] ""  Autopilot
 SG_ Index2 : 63|1@1+ (1,0) [0|1] ""  Autopilot

BO_ 1082 RadarPoint21_A: 8 Radar
 SG_ LongDist : 0|12@1+ (0.0625,0) [0|255.9] "meters"  Autopilot
 SG_ LongSpeed : 12|12@1+ (0.0625,-128) [-128|128] "meters/sec"  Autopilot
 SG_ LatDist : 24|11@1+ (0.125,-128) [-128|128] "meters"  Autopilot
 SG_ ProbExist : 35|5@1+ (3.125,0) [0|96.875] "%"  Autopilot
 SG_ LongAccel : 40|10@1+ (0.03125,-16) [-16|16] "meters/sec/sec"  Autopilot
 SG_ ProbObstacle : 50|5@1+ (3.125,0) [0|96.875] "%"  Autopilot
 SG_ Valid : 55|1@1+ (1,0) [0|1] ""  Autopilot
 SG_ ProbNonObstacle : 56|5@1+ (3.125,0) [0|96.875] "%"  Autopilot
 SG_ Meas : 61|1@1+ (1,0) [0|1] ""  Autopilot
 SG_ Tracked : 62|1@1+ (1,0) [0|1] ""  Autopilot
 SG_ Index : 63|1@1+ (1,0) [0|1] ""  Autopilot

BO_ 1083 RadarPoint21_B: 8 Radar
 SG_ LatSpeed : 0|10@1+ (0.125,-64) [-64|64] "meters/sec"  Autopilot
 SG_ Length : 10|6@1+ (0.125,0) [0|7.875] "m"  Autopilot
 SG_ dZ : 16|6@1+ (0.25,-5) [-5|10.75] "m"  Autopilot
 SG_ MovingState : 22|2@1+ (1,0) [0|3] ""  Autopilot
 SG_ dxSigma : 24|6@1+ (1,0) [0|63] ""  Autopilot
 SG_ vxSigma : 30|6@1+ (1,0) [0|63] ""  Autopilot
 SG_ axSigma : 36|6@1+ (1,0) [0|63] ""  Autopilot
 SG_ dySigma : 42|6@1+ (1,0) [0|63] ""  Autopilot
 SG_ ProbClass : 48|5@1+ (3.125,0) [0|96.875] "%"  Autopilot
 SG_ Class : 53|3@1+ (1,0) [0|7] ""  Autopilot
 SG_ dxRearEndLoss : 56|6@1+ (1,0) [0|63] ""  Autopilot
 SG_ NotUsed : 62|1@1+ (1,0) [0|1] ""  Autopilot
 SG_ Index2 : 63|1@1+ (1,0) [0|1] ""  Autopilot

BO_ 1084 RadarPoint22_A: 8 Radar
 SG_ LongDist : 0|12@1+ (0.0625,0) [0|255.9] "meters"  Autopilot
 SG_ LongSpeed : 12|12@1+ (0.0625,-128) [-128|128] "meters/sec"  Autopilot
 SG_ LatDist : 24|11@1+ (0.125,-128) [-128|128] "meters"  Autopilot
 SG_ ProbExist : 35|5@1+ (3.125,0) [0|96.875] "%"  Autopilot
 SG_ LongAccel : 40|10@1+ (0.03125,-16) [-16|16] "meters/sec/sec"  Autopilot
 SG_ ProbObstacle : 50|5@1+ (3.125,0) [0|96.875] "%"  Autopilot
 SG_ Valid : 55|1@1+ (1,0) [0|1] ""  Autopilot
 SG_ ProbNonObstacle : 56|5@1+ (3.125,0) [0|96.875] "%"  Autopilot
 SG_ Meas : 61|1@1+ (1,0) [0|1] ""  Autopilot
 SG_ Tracked : 62|1@1+ (1,0) [0|1] ""  Autopilot
 SG_ Index : 63|1@1+ (1,0) [0|1] ""  Autopilot

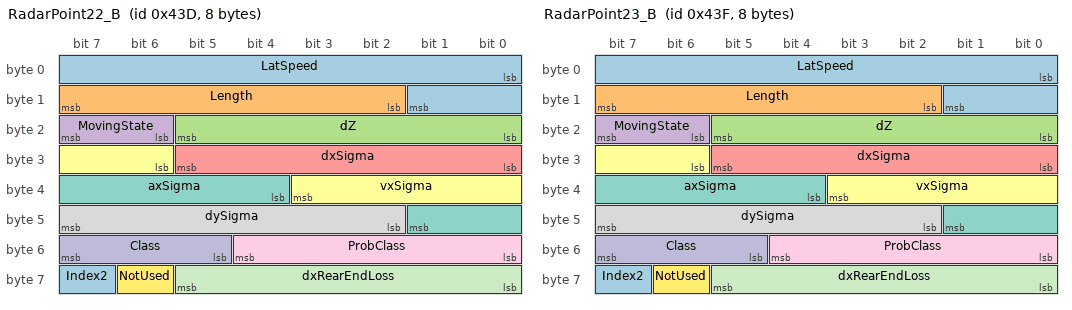
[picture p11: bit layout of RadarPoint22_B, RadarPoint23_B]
BO_ 1085 RadarPoint22_B: 8 Radar
 SG_ LatSpeed : 0|10@1+ (0.125,-64) [-64|64] "meters/sec"  Autopilot
 SG_ Length : 10|6@1+ (0.125,0) [0|7.875] "m"  Autopilot
 SG_ dZ : 16|6@1+ (0.25,-5) [-5|10.75] "m"  Autopilot
 SG_ MovingState : 22|2@1+ (1,0) [0|3] ""  Autopilot
 SG_ dxSigma : 24|6@1+ (1,0) [0|63] ""  Autopilot
 SG_ vxSigma : 30|6@1+ (1,0) [0|63] ""  Autopilot
 SG_ axSigma : 36|6@1+ (1,0) [0|63] ""  Autopilot
 SG_ dySigma : 42|6@1+ (1,0) [0|63] ""  Autopilot
 SG_ ProbClass : 48|5@1+ (3.125,0) [0|96.875] "%"  Autopilot
 SG_ Class : 53|3@1+ (1,0) [0|7] ""  Autopilot
 SG_ dxRearEndLoss : 56|6@1+ (1,0) [0|63] ""  Autopilot
 SG_ NotUsed : 62|1@1+ (1,0) [0|1] ""  Autopilot
 SG_ Index2 : 63|1@1+ (1,0) [0|1] ""  Autopilot

BO_ 1086 RadarPoint23_A: 8 Radar
 SG_ LongDist : 0|12@1+ (0.0625,0) [0|255.9] "meters"  Autopilot
 SG_ LongSpeed : 12|12@1+ (0.0625,-128) [-128|128] "meters/sec"  Autopilot
 SG_ LatDist : 24|11@1+ (0.125,-128) [-128|128] "meters"  Autopilot
 SG_ ProbExist : 35|5@1+ (3.125,0) [0|96.875] "%"  Autopilot
 SG_ LongAccel : 40|10@1+ (0.03125,-16) [-16|16] "meters/sec/sec"  Autopilot
 SG_ ProbObstacle : 50|5@1+ (3.125,0) [0|96.875] "%"  Autopilot
 SG_ Valid : 55|1@1+ (1,0) [0|1] ""  Autopilot
 SG_ ProbNonObstacle : 56|5@1+ (3.125,0) [0|96.875] "%"  Autopilot
 SG_ Meas : 61|1@1+ (1,0) [0|1] ""  Autopilot
 SG_ Tracked : 62|1@1+ (1,0) [0|1] ""  Autopilot
 SG_ Index : 63|1@1+ (1,0) [0|1] ""  Autopilot

BO_ 1087 RadarPoint23_B: 8 Radar
 SG_ LatSpeed : 0|10@1+ (0.125,-64) [-64|64] "meters/sec"  Autopilot
 SG_ Length : 10|6@1+ (0.125,0) [0|7.875] "m"  Autopilot
 SG_ dZ : 16|6@1+ (0.25,-5) [-5|10.75] "m"  Autopilot
 SG_ MovingState : 22|2@1+ (1,0) [0|3] ""  Autopilot
 SG_ dxSigma : 24|6@1+ (1,0) [0|63] ""  Autopilot
 SG_ vxSigma : 30|6@1+ (1,0) [0|63] ""  Autopilot
 SG_ axSigma : 36|6@1+ (1,0) [0|63] ""  Autopilot
 SG_ dySigma : 42|6@1+ (1,0) [0|63] ""  Autopilot
 SG_ ProbClass : 48|5@1+ (3.125,0) [0|96.875] "%"  Autopilot
 SG_ Class : 53|3@1+ (1,0) [0|7] ""  Autopilot
 SG_ dxRearEndLoss : 56|6@1+ (1,0) [0|63] ""  Autopilot
 SG_ NotUsed : 62|1@1+ (1,0) [0|1] ""  Autopilot
 SG_ Index2 : 63|1@1+ (1,0) [0|1] ""  Autopilot

BO_ 1088 RadarPoint24_A: 8 Radar
 SG_ LongDist : 0|12@1+ (0.0625,0) [0|255.9] "meters"  Autopilot
 SG_ LongSpeed : 12|12@1+ (0.0625,-128) [-128|128] "meters/sec"  Autopilot
 SG_ LatDist : 24|11@1+ (0.125,-128) [-128|128] "meters"  Autopilot
 SG_ ProbExist : 35|5@1+ (3.125,0) [0|96.875] "%"  Autopilot
 SG_ LongAccel : 40|10@1+ (0.03125,-16) [-16|16] "meters/sec/sec"  Autopilot
 SG_ ProbObstacle : 50|5@1+ (3.125,0) [0|96.875] "%"  Autopilot
 SG_ Valid : 55|1@1+ (1,0) [0|1] ""  Autopilot
 SG_ ProbNonObstacle : 56|5@1+ (3.125,0) [0|96.875] "%"  Autopilot
 SG_ Meas : 61|1@1+ (1,0) [0|1] ""  Autopilot
 SG_ Tracked : 62|1@1+ (1,0) [0|1] ""  Autopilot
 SG_ Index : 63|1@1+ (1,0) [0|1] ""  Autopilot

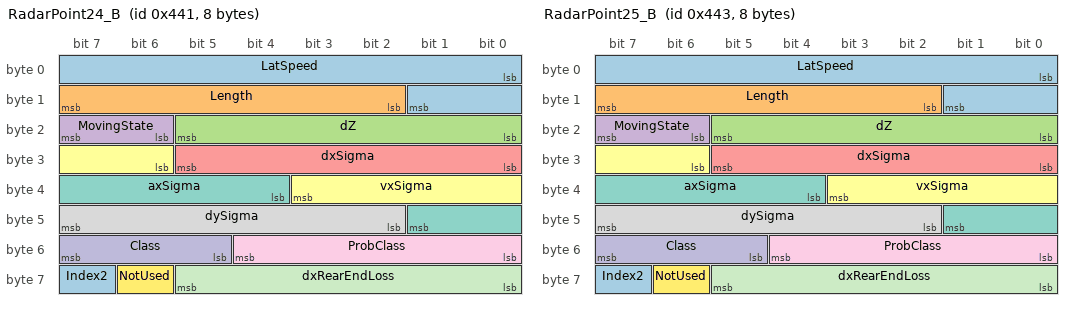
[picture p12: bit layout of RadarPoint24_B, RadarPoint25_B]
BO_ 1089 RadarPoint24_B: 8 Radar
 SG_ LatSpeed : 0|10@1+ (0.125,-64) [-64|64] "meters/sec"  Autopilot
 SG_ Length : 10|6@1+ (0.125,0) [0|7.875] "m"  Autopilot
 SG_ dZ : 16|6@1+ (0.25,-5) [-5|10.75] "m"  Autopilot
 SG_ MovingState : 22|2@1+ (1,0) [0|3] ""  Autopilot
 SG_ dxSigma : 24|6@1+ (1,0) [0|63] ""  Autopilot
 SG_ vxSigma : 30|6@1+ (1,0) [0|63] ""  Autopilot
 SG_ axSigma : 36|6@1+ (1,0) [0|63] ""  Autopilot
 SG_ dySigma : 42|6@1+ (1,0) [0|63] ""  Autopilot
 SG_ ProbClass : 48|5@1+ (3.125,0) [0|96.875] "%"  Autopilot
 SG_ Class : 53|3@1+ (1,0) [0|7] ""  Autopilot
 SG_ dxRearEndLoss : 56|6@1+ (1,0) [0|63] ""  Autopilot
 SG_ NotUsed : 62|1@1+ (1,0) [0|1] ""  Autopilot
 SG_ Index2 : 63|1@1+ (1,0) [0|1] ""  Autopilot

BO_ 1090 RadarPoint25_A: 8 Radar
 SG_ LongDist : 0|12@1+ (0.0625,0) [0|255.9] "meters"  Autopilot
 SG_ LongSpeed : 12|12@1+ (0.0625,-128) [-128|128] "meters/sec"  Autopilot
 SG_ LatDist : 24|11@1+ (0.125,-128) [-128|128] "meters"  Autopilot
 SG_ ProbExist : 35|5@1+ (3.125,0) [0|96.875] "%"  Autopilot
 SG_ LongAccel : 40|10@1+ (0.03125,-16) [-16|16] "meters/sec/sec"  Autopilot
 SG_ ProbObstacle : 50|5@1+ (3.125,0) [0|96.875] "%"  Autopilot
 SG_ Valid : 55|1@1+ (1,0) [0|1] ""  Autopilot
 SG_ ProbNonObstacle : 56|5@1+ (3.125,0) [0|96.875] "%"  Autopilot
 SG_ Meas : 61|1@1+ (1,0) [0|1] ""  Autopilot
 SG_ Tracked : 62|1@1+ (1,0) [0|1] ""  Autopilot
 SG_ Index : 63|1@1+ (1,0) [0|1] ""  Autopilot

BO_ 1091 RadarPoint25_B: 8 Radar
 SG_ LatSpeed : 0|10@1+ (0.125,-64) [-64|64] "meters/sec"  Autopilot
 SG_ Length : 10|6@1+ (0.125,0) [0|7.875] "m"  Autopilot
 SG_ dZ : 16|6@1+ (0.25,-5) [-5|10.75] "m"  Autopilot
 SG_ MovingState : 22|2@1+ (1,0) [0|3] ""  Autopilot
 SG_ dxSigma : 24|6@1+ (1,0) [0|63] ""  Autopilot
 SG_ vxSigma : 30|6@1+ (1,0) [0|63] ""  Autopilot
 SG_ axSigma : 36|6@1+ (1,0) [0|63] ""  Autopilot
 SG_ dySigma : 42|6@1+ (1,0) [0|63] ""  Autopilot
 SG_ ProbClass : 48|5@1+ (3.125,0) [0|96.875] "%"  Autopilot
 SG_ Class : 53|3@1+ (1,0) [0|7] ""  Autopilot
 SG_ dxRearEndLoss : 56|6@1+ (1,0) [0|63] ""  Autopilot
 SG_ NotUsed : 62|1@1+ (1,0) [0|1] ""  Autopilot
 SG_ Index2 : 63|1@1+ (1,0) [0|1] ""  Autopilot

BO_ 1092 RadarPoint26_A: 8 Radar
 SG_ LongDist : 0|12@1+ (0.0625,0) [0|255.9] "meters"  Autopilot
 SG_ LongSpeed : 12|12@1+ (0.0625,-128) [-128|128] "meters/sec"  Autopilot
 SG_ LatDist : 24|11@1+ (0.125,-128) [-128|128] "meters"  Autopilot
 SG_ ProbExist : 35|5@1+ (3.125,0) [0|96.875] "%"  Autopilot
 SG_ LongAccel : 40|10@1+ (0.03125,-16) [-16|16] "meters/sec/sec"  Autopilot
 SG_ ProbObstacle : 50|5@1+ (3.125,0) [0|96.875] "%"  Autopilot
 SG_ Valid : 55|1@1+ (1,0) [0|1] ""  Autopilot
 SG_ ProbNonObstacle : 56|5@1+ (3.125,0) [0|96.875] "%"  Autopilot
 SG_ Meas : 61|1@1+ (1,0) [0|1] ""  Autopilot
 SG_ Tracked : 62|1@1+ (1,0) [0|1] ""  Autopilot
 SG_ Index : 63|1@1+ (1,0) [0|1] ""  Autopilot

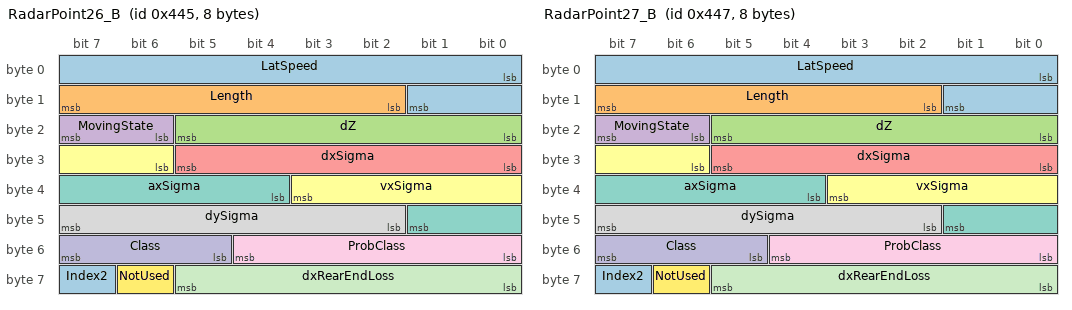
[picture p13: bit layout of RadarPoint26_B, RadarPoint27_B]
BO_ 1093 RadarPoint26_B: 8 Radar
 SG_ LatSpeed : 0|10@1+ (0.125,-64) [-64|64] "meters/sec"  Autopilot
 SG_ Length : 10|6@1+ (0.125,0) [0|7.875] "m"  Autopilot
 SG_ dZ : 16|6@1+ (0.25,-5) [-5|10.75] "m"  Autopilot
 SG_ MovingState : 22|2@1+ (1,0) [0|3] ""  Autopilot
 SG_ dxSigma : 24|6@1+ (1,0) [0|63] ""  Autopilot
 SG_ vxSigma : 30|6@1+ (1,0) [0|63] ""  Autopilot
 SG_ axSigma : 36|6@1+ (1,0) [0|63] ""  Autopilot
 SG_ dySigma : 42|6@1+ (1,0) [0|63] ""  Autopilot
 SG_ ProbClass : 48|5@1+ (3.125,0) [0|96.875] "%"  Autopilot
 SG_ Class : 53|3@1+ (1,0) [0|7] ""  Autopilot
 SG_ dxRearEndLoss : 56|6@1+ (1,0) [0|63] ""  Autopilot
 SG_ NotUsed : 62|1@1+ (1,0) [0|1] ""  Autopilot
 SG_ Index2 : 63|1@1+ (1,0) [0|1] ""  Autopilot

BO_ 1094 RadarPoint27_A: 8 Radar
 SG_ LongDist : 0|12@1+ (0.0625,0) [0|255.9] "meters"  Autopilot
 SG_ LongSpeed : 12|12@1+ (0.0625,-128) [-128|128] "meters/sec"  Autopilot
 SG_ LatDist : 24|11@1+ (0.125,-128) [-128|128] "meters"  Autopilot
 SG_ ProbExist : 35|5@1+ (3.125,0) [0|96.875] "%"  Autopilot
 SG_ LongAccel : 40|10@1+ (0.03125,-16) [-16|16] "meters/sec/sec"  Autopilot
 SG_ ProbObstacle : 50|5@1+ (3.125,0) [0|96.875] "%"  Autopilot
 SG_ Valid : 55|1@1+ (1,0) [0|1] ""  Autopilot
 SG_ ProbNonObstacle : 56|5@1+ (3.125,0) [0|96.875] "%"  Autopilot
 SG_ Meas : 61|1@1+ (1,0) [0|1] ""  Autopilot
 SG_ Tracked : 62|1@1+ (1,0) [0|1] ""  Autopilot
 SG_ Index : 63|1@1+ (1,0) [0|1] ""  Autopilot

BO_ 1095 RadarPoint27_B: 8 Radar
 SG_ LatSpeed : 0|10@1+ (0.125,-64) [-64|64] "meters/sec"  Autopilot
 SG_ Length : 10|6@1+ (0.125,0) [0|7.875] "m"  Autopilot
 SG_ dZ : 16|6@1+ (0.25,-5) [-5|10.75] "m"  Autopilot
 SG_ MovingState : 22|2@1+ (1,0) [0|3] ""  Autopilot
 SG_ dxSigma : 24|6@1+ (1,0) [0|63] ""  Autopilot
 SG_ vxSigma : 30|6@1+ (1,0) [0|63] ""  Autopilot
 SG_ axSigma : 36|6@1+ (1,0) [0|63] ""  Autopilot
 SG_ dySigma : 42|6@1+ (1,0) [0|63] ""  Autopilot
 SG_ ProbClass : 48|5@1+ (3.125,0) [0|96.875] "%"  Autopilot
 SG_ Class : 53|3@1+ (1,0) [0|7] ""  Autopilot
 SG_ dxRearEndLoss : 56|6@1+ (1,0) [0|63] ""  Autopilot
 SG_ NotUsed : 62|1@1+ (1,0) [0|1] ""  Autopilot
 SG_ Index2 : 63|1@1+ (1,0) [0|1] ""  Autopilot

BO_ 1096 RadarPoint28_A: 8 Radar
 SG_ LongDist : 0|12@1+ (0.0625,0) [0|255.9] "meters"  Autopilot
 SG_ LongSpeed : 12|12@1+ (0.0625,-128) [-128|128] "meters/sec"  Autopilot
 SG_ LatDist : 24|11@1+ (0.125,-128) [-128|128] "meters"  Autopilot
 SG_ ProbExist : 35|5@1+ (3.125,0) [0|96.875] "%"  Autopilot
 SG_ LongAccel : 40|10@1+ (0.03125,-16) [-16|16] "meters/sec/sec"  Autopilot
 SG_ ProbObstacle : 50|5@1+ (3.125,0) [0|96.875] "%"  Autopilot
 SG_ Valid : 55|1@1+ (1,0) [0|1] ""  Autopilot
 SG_ ProbNonObstacle : 56|5@1+ (3.125,0) [0|96.875] "%"  Autopilot
 SG_ Meas : 61|1@1+ (1,0) [0|1] ""  Autopilot
 SG_ Tracked : 62|1@1+ (1,0) [0|1] ""  Autopilot
 SG_ Index : 63|1@1+ (1,0) [0|1] ""  Autopilot

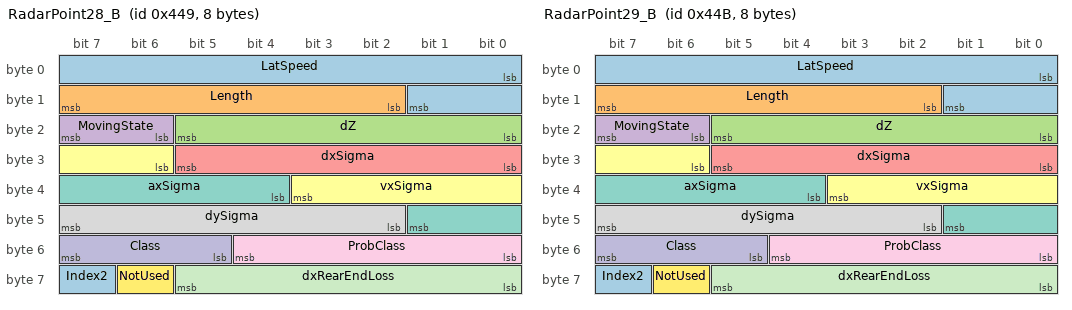
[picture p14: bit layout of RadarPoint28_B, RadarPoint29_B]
BO_ 1097 RadarPoint28_B: 8 Radar
 SG_ LatSpeed : 0|10@1+ (0.125,-64) [-64|64] "meters/sec"  Autopilot
 SG_ Length : 10|6@1+ (0.125,0) [0|7.875] "m"  Autopilot
 SG_ dZ : 16|6@1+ (0.25,-5) [-5|10.75] "m"  Autopilot
 SG_ MovingState : 22|2@1+ (1,0) [0|3] ""  Autopilot
 SG_ dxSigma : 24|6@1+ (1,0) [0|63] ""  Autopilot
 SG_ vxSigma : 30|6@1+ (1,0) [0|63] ""  Autopilot
 SG_ axSigma : 36|6@1+ (1,0) [0|63] ""  Autopilot
 SG_ dySigma : 42|6@1+ (1,0) [0|63] ""  Autopilot
 SG_ ProbClass : 48|5@1+ (3.125,0) [0|96.875] "%"  Autopilot
 SG_ Class : 53|3@1+ (1,0) [0|7] ""  Autopilot
 SG_ dxRearEndLoss : 56|6@1+ (1,0) [0|63] ""  Autopilot
 SG_ NotUsed : 62|1@1+ (1,0) [0|1] ""  Autopilot
 SG_ Index2 : 63|1@1+ (1,0) [0|1] ""  Autopilot

BO_ 1098 RadarPoint29_A: 8 Radar
 SG_ LongDist : 0|12@1+ (0.0625,0) [0|255.9] "meters"  Autopilot
 SG_ LongSpeed : 12|12@1+ (0.0625,-128) [-128|128] "meters/sec"  Autopilot
 SG_ LatDist : 24|11@1+ (0.125,-128) [-128|128] "meters"  Autopilot
 SG_ ProbExist : 35|5@1+ (3.125,0) [0|96.875] "%"  Autopilot
 SG_ LongAccel : 40|10@1+ (0.03125,-16) [-16|16] "meters/sec/sec"  Autopilot
 SG_ ProbObstacle : 50|5@1+ (3.125,0) [0|96.875] "%"  Autopilot
 SG_ Valid : 55|1@1+ (1,0) [0|1] ""  Autopilot
 SG_ ProbNonObstacle : 56|5@1+ (3.125,0) [0|96.875] "%"  Autopilot
 SG_ Meas : 61|1@1+ (1,0) [0|1] ""  Autopilot
 SG_ Tracked : 62|1@1+ (1,0) [0|1] ""  Autopilot
 SG_ Index : 63|1@1+ (1,0) [0|1] ""  Autopilot

BO_ 1099 RadarPoint29_B: 8 Radar
 SG_ LatSpeed : 0|10@1+ (0.125,-64) [-64|64] "meters/sec"  Autopilot
 SG_ Length : 10|6@1+ (0.125,0) [0|7.875] "m"  Autopilot
 SG_ dZ : 16|6@1+ (0.25,-5) [-5|10.75] "m"  Autopilot
 SG_ MovingState : 22|2@1+ (1,0) [0|3] ""  Autopilot
 SG_ dxSigma : 24|6@1+ (1,0) [0|63] ""  Autopilot
 SG_ vxSigma : 30|6@1+ (1,0) [0|63] ""  Autopilot
 SG_ axSigma : 36|6@1+ (1,0) [0|63] ""  Autopilot
 SG_ dySigma : 42|6@1+ (1,0) [0|63] ""  Autopilot
 SG_ ProbClass : 48|5@1+ (3.125,0) [0|96.875] "%"  Autopilot
 SG_ Class : 53|3@1+ (1,0) [0|7] ""  Autopilot
 SG_ dxRearEndLoss : 56|6@1+ (1,0) [0|63] ""  Autopilot
 SG_ NotUsed : 62|1@1+ (1,0) [0|1] ""  Autopilot
 SG_ Index2 : 63|1@1+ (1,0) [0|1] ""  Autopilot

BO_ 1100 RadarPoint30_A: 8 Radar
 SG_ LongDist : 0|12@1+ (0.0625,0) [0|255.9] "meters"  Autopilot
 SG_ LongSpeed : 12|12@1+ (0.0625,-128) [-128|128] "meters/sec"  Autopilot
 SG_ LatDist : 24|11@1+ (0.125,-128) [-128|128] "meters"  Autopilot
 SG_ ProbExist : 35|5@1+ (3.125,0) [0|96.875] "%"  Autopilot
 SG_ LongAccel : 40|10@1+ (0.03125,-16) [-16|16] "meters/sec/sec"  Autopilot
 SG_ ProbObstacle : 50|5@1+ (3.125,0) [0|96.875] "%"  Autopilot
 SG_ Valid : 55|1@1+ (1,0) [0|1] ""  Autopilot
 SG_ ProbNonObstacle : 56|5@1+ (3.125,0) [0|96.875] "%"  Autopilot
 SG_ Meas : 61|1@1+ (1,0) [0|1] ""  Autopilot
 SG_ Tracked : 62|1@1+ (1,0) [0|1] ""  Autopilot
 SG_ Index : 63|1@1+ (1,0) [0|1] ""  Autopilot

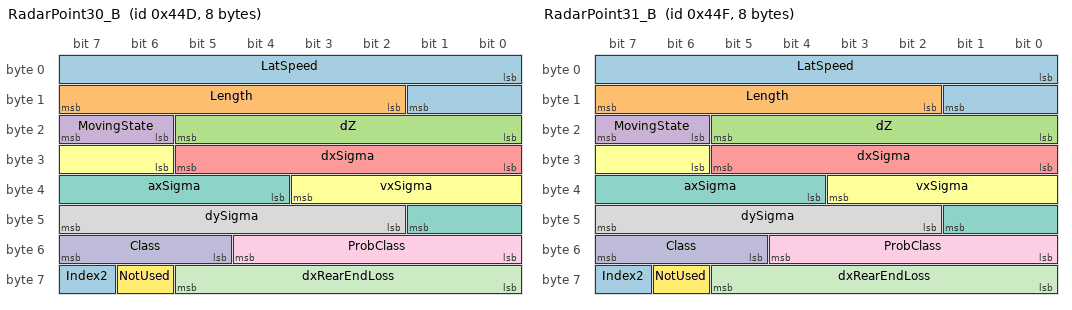
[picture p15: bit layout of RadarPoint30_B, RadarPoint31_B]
BO_ 1101 RadarPoint30_B: 8 Radar
 SG_ LatSpeed : 0|10@1+ (0.125,-64) [-64|64] "meters/sec"  Autopilot
 SG_ Length : 10|6@1+ (0.125,0) [0|7.875] "m"  Autopilot
 SG_ dZ : 16|6@1+ (0.25,-5) [-5|10.75] "m"  Autopilot
 SG_ MovingState : 22|2@1+ (1,0) [0|3] ""  Autopilot
 SG_ dxSigma : 24|6@1+ (1,0) [0|63] ""  Autopilot
 SG_ vxSigma : 30|6@1+ (1,0) [0|63] ""  Autopilot
 SG_ axSigma : 36|6@1+ (1,0) [0|63] ""  Autopilot
 SG_ dySigma : 42|6@1+ (1,0) [0|63] ""  Autopilot
 SG_ ProbClass : 48|5@1+ (3.125,0) [0|96.875] "%"  Autopilot
 SG_ Class : 53|3@1+ (1,0) [0|7] ""  Autopilot
 SG_ dxRearEndLoss : 56|6@1+ (1,0) [0|63] ""  Autopilot
 SG_ NotUsed : 62|1@1+ (1,0) [0|1] ""  Autopilot
 SG_ Index2 : 63|1@1+ (1,0) [0|1] ""  Autopilot

BO_ 1102 RadarPoint31_A: 8 Radar
 SG_ LongDist : 0|12@1+ (0.0625,0) [0|255.9] "meters"  Autopilot
 SG_ LongSpeed : 12|12@1+ (0.0625,-128) [-128|128] "meters/sec"  Autopilot
 SG_ LatDist : 24|11@1+ (0.125,-128) [-128|128] "meters"  Autopilot
 SG_ ProbExist : 35|5@1+ (3.125,0) [0|96.875] "%"  Autopilot
 SG_ LongAccel : 40|10@1+ (0.03125,-16) [-16|16] "meters/sec/sec"  Autopilot
 SG_ ProbObstacle : 50|5@1+ (3.125,0) [0|96.875] "%"  Autopilot
 SG_ Valid : 55|1@1+ (1,0) [0|1] ""  Autopilot
 SG_ ProbNonObstacle : 56|5@1+ (3.125,0) [0|96.875] "%"  Autopilot
 SG_ Meas : 61|1@1+ (1,0) [0|1] ""  Autopilot
 SG_ Tracked : 62|1@1+ (1,0) [0|1] ""  Autopilot
 SG_ Index : 63|1@1+ (1,0) [0|1] ""  Autopilot

BO_ 1103 RadarPoint31_B: 8 Radar
 SG_ LatSpeed : 0|10@1+ (0.125,-64) [-64|64] "meters/sec"  Autopilot
 SG_ Length : 10|6@1+ (0.125,0) [0|7.875] "m"  Autopilot
 SG_ dZ : 16|6@1+ (0.25,-5) [-5|10.75] "m"  Autopilot
 SG_ MovingState : 22|2@1+ (1,0) [0|3] ""  Autopilot
 SG_ dxSigma : 24|6@1+ (1,0) [0|63] ""  Autopilot
 SG_ vxSigma : 30|6@1+ (1,0) [0|63] ""  Autopilot
 SG_ axSigma : 36|6@1+ (1,0) [0|63] ""  Autopilot
 SG_ dySigma : 42|6@1+ (1,0) [0|63] ""  Autopilot
 SG_ ProbClass : 48|5@1+ (3.125,0) [0|96.875] "%"  Autopilot
 SG_ Class : 53|3@1+ (1,0) [0|7] ""  Autopilot
 SG_ dxRearEndLoss : 56|6@1+ (1,0) [0|63] ""  Autopilot
 SG_ NotUsed : 62|1@1+ (1,0) [0|1] ""  Autopilot
 SG_ Index2 : 63|1@1+ (1,0) [0|1] ""  Autopilot

BO_ 1104 RadarPoint32_A: 8 Radar
 SG_ LongDist : 0|12@1+ (0.0625,0) [0|255.9] "meters"  Autopilot
 SG_ LongSpeed : 12|12@1+ (0.0625,-128) [-128|128] "meters/sec"  Autopilot
 SG_ LatDist : 24|11@1+ (0.125,-128) [-128|128] "meters"  Autopilot
 SG_ ProbExist : 35|5@1+ (3.125,0) [0|96.875] "%"  Autopilot
 SG_ LongAccel : 40|10@1+ (0.03125,-16) [-16|16] "meters/sec/sec"  Autopilot
 SG_ ProbObstacle : 50|5@1+ (3.125,0) [0|96.875] "%"  Autopilot
 SG_ Valid : 55|1@1+ (1,0) [0|1] ""  Autopilot
 SG_ ProbNonObstacle : 56|5@1+ (3.125,0) [0|96.875] "%"  Autopilot
 SG_ Meas : 61|1@1+ (1,0) [0|1] ""  Autopilot
 SG_ Tracked : 62|1@1+ (1,0) [0|1] ""  Autopilot
 SG_ Index : 63|1@1+ (1,0) [0|1] ""  Autopilot

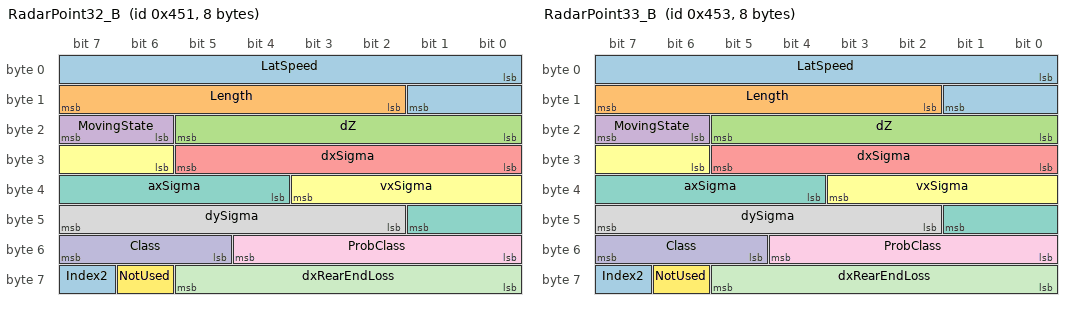
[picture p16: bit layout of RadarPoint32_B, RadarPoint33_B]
BO_ 1105 RadarPoint32_B: 8 Radar
 SG_ LatSpeed : 0|10@1+ (0.125,-64) [-64|64] "meters/sec"  Autopilot
 SG_ Length : 10|6@1+ (0.125,0) [0|7.875] "m"  Autopilot
 SG_ dZ : 16|6@1+ (0.25,-5) [-5|10.75] "m"  Autopilot
 SG_ MovingState : 22|2@1+ (1,0) [0|3] ""  Autopilot
 SG_ dxSigma : 24|6@1+ (1,0) [0|63] ""  Autopilot
 SG_ vxSigma : 30|6@1+ (1,0) [0|63] ""  Autopilot
 SG_ axSigma : 36|6@1+ (1,0) [0|63] ""  Autopilot
 SG_ dySigma : 42|6@1+ (1,0) [0|63] ""  Autopilot
 SG_ ProbClass : 48|5@1+ (3.125,0) [0|96.875] "%"  Autopilot
 SG_ Class : 53|3@1+ (1,0) [0|7] ""  Autopilot
 SG_ dxRearEndLoss : 56|6@1+ (1,0) [0|63] ""  Autopilot
 SG_ NotUsed : 62|1@1+ (1,0) [0|1] ""  Autopilot
 SG_ Index2 : 63|1@1+ (1,0) [0|1] ""  Autopilot

BO_ 1106 RadarPoint33_A: 8 Radar
 SG_ LongDist : 0|12@1+ (0.0625,0) [0|255.9] "meters"  Autopilot
 SG_ LongSpeed : 12|12@1+ (0.0625,-128) [-128|128] "meters/sec"  Autopilot
 SG_ LatDist : 24|11@1+ (0.125,-128) [-128|128] "meters"  Autopilot
 SG_ ProbExist : 35|5@1+ (3.125,0) [0|96.875] "%"  Autopilot
 SG_ LongAccel : 40|10@1+ (0.03125,-16) [-16|16] "meters/sec/sec"  Autopilot
 SG_ ProbObstacle : 50|5@1+ (3.125,0) [0|96.875] "%"  Autopilot
 SG_ Valid : 55|1@1+ (1,0) [0|1] ""  Autopilot
 SG_ ProbNonObstacle : 56|5@1+ (3.125,0) [0|96.875] "%"  Autopilot
 SG_ Meas : 61|1@1+ (1,0) [0|1] ""  Autopilot
 SG_ Tracked : 62|1@1+ (1,0) [0|1] ""  Autopilot
 SG_ Index : 63|1@1+ (1,0) [0|1] ""  Autopilot

BO_ 1107 RadarPoint33_B: 8 Radar
 SG_ LatSpeed : 0|10@1+ (0.125,-64) [-64|64] "meters/sec"  Autopilot
 SG_ Length : 10|6@1+ (0.125,0) [0|7.875] "m"  Autopilot
 SG_ dZ : 16|6@1+ (0.25,-5) [-5|10.75] "m"  Autopilot
 SG_ MovingState : 22|2@1+ (1,0) [0|3] ""  Autopilot
 SG_ dxSigma : 24|6@1+ (1,0) [0|63] ""  Autopilot
 SG_ vxSigma : 30|6@1+ (1,0) [0|63] ""  Autopilot
 SG_ axSigma : 36|6@1+ (1,0) [0|63] ""  Autopilot
 SG_ dySigma : 42|6@1+ (1,0) [0|63] ""  Autopilot
 SG_ ProbClass : 48|5@1+ (3.125,0) [0|96.875] "%"  Autopilot
 SG_ Class : 53|3@1+ (1,0) [0|7] ""  Autopilot
 SG_ dxRearEndLoss : 56|6@1+ (1,0) [0|63] ""  Autopilot
 SG_ NotUsed : 62|1@1+ (1,0) [0|1] ""  Autopilot
 SG_ Index2 : 63|1@1+ (1,0) [0|1] ""  Autopilot

BO_ 1108 RadarPoint34_A: 8 Radar
 SG_ LongDist : 0|12@1+ (0.0625,0) [0|255.9] "meters"  Autopilot
 SG_ LongSpeed : 12|12@1+ (0.0625,-128) [-128|128] "meters/sec"  Autopilot
 SG_ LatDist : 24|11@1+ (0.125,-128) [-128|128] "meters"  Autopilot
 SG_ ProbExist : 35|5@1+ (3.125,0) [0|96.875] "%"  Autopilot
 SG_ LongAccel : 40|10@1+ (0.03125,-16) [-16|16] "meters/sec/sec"  Autopilot
 SG_ ProbObstacle : 50|5@1+ (3.125,0) [0|96.875] "%"  Autopilot
 SG_ Valid : 55|1@1+ (1,0) [0|1] ""  Autopilot
 SG_ ProbNonObstacle : 56|5@1+ (3.125,0) [0|96.875] "%"  Autopilot
 SG_ Meas : 61|1@1+ (1,0) [0|1] ""  Autopilot
 SG_ Tracked : 62|1@1+ (1,0) [0|1] ""  Autopilot
 SG_ Index : 63|1@1+ (1,0) [0|1] ""  Autopilot

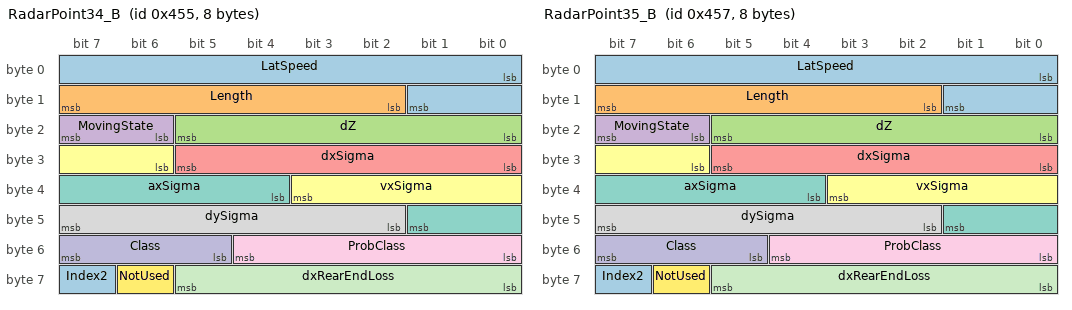
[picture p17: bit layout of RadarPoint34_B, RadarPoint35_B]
BO_ 1109 RadarPoint34_B: 8 Radar
 SG_ LatSpeed : 0|10@1+ (0.125,-64) [-64|64] "meters/sec"  Autopilot
 SG_ Length : 10|6@1+ (0.125,0) [0|7.875] "m"  Autopilot
 SG_ dZ : 16|6@1+ (0.25,-5) [-5|10.75] "m"  Autopilot
 SG_ MovingState : 22|2@1+ (1,0) [0|3] ""  Autopilot
 SG_ dxSigma : 24|6@1+ (1,0) [0|63] ""  Autopilot
 SG_ vxSigma : 30|6@1+ (1,0) [0|63] ""  Autopilot
 SG_ axSigma : 36|6@1+ (1,0) [0|63] ""  Autopilot
 SG_ dySigma : 42|6@1+ (1,0) [0|63] ""  Autopilot
 SG_ ProbClass : 48|5@1+ (3.125,0) [0|96.875] "%"  Autopilot
 SG_ Class : 53|3@1+ (1,0) [0|7] ""  Autopilot
 SG_ dxRearEndLoss : 56|6@1+ (1,0) [0|63] ""  Autopilot
 SG_ NotUsed : 62|1@1+ (1,0) [0|1] ""  Autopilot
 SG_ Index2 : 63|1@1+ (1,0) [0|1] ""  Autopilot

BO_ 1110 RadarPoint35_A: 8 Radar
 SG_ LongDist : 0|12@1+ (0.0625,0) [0|255.9] "meters"  Autopilot
 SG_ LongSpeed : 12|12@1+ (0.0625,-128) [-128|128] "meters/sec"  Autopilot
 SG_ LatDist : 24|11@1+ (0.125,-128) [-128|128] "meters"  Autopilot
 SG_ ProbExist : 35|5@1+ (3.125,0) [0|96.875] "%"  Autopilot
 SG_ LongAccel : 40|10@1+ (0.03125,-16) [-16|16] "meters/sec/sec"  Autopilot
 SG_ ProbObstacle : 50|5@1+ (3.125,0) [0|96.875] "%"  Autopilot
 SG_ Valid : 55|1@1+ (1,0) [0|1] ""  Autopilot
 SG_ ProbNonObstacle : 56|5@1+ (3.125,0) [0|96.875] "%"  Autopilot
 SG_ Meas : 61|1@1+ (1,0) [0|1] ""  Autopilot
 SG_ Tracked : 62|1@1+ (1,0) [0|1] ""  Autopilot
 SG_ Index : 63|1@1+ (1,0) [0|1] ""  Autopilot

BO_ 1111 RadarPoint35_B: 8 Radar
 SG_ LatSpeed : 0|10@1+ (0.125,-64) [-64|64] "meters/sec"  Autopilot
 SG_ Length : 10|6@1+ (0.125,0) [0|7.875] "m"  Autopilot
 SG_ dZ : 16|6@1+ (0.25,-5) [-5|10.75] "m"  Autopilot
 SG_ MovingState : 22|2@1+ (1,0) [0|3] ""  Autopilot
 SG_ dxSigma : 24|6@1+ (1,0) [0|63] ""  Autopilot
 SG_ vxSigma : 30|6@1+ (1,0) [0|63] ""  Autopilot
 SG_ axSigma : 36|6@1+ (1,0) [0|63] ""  Autopilot
 SG_ dySigma : 42|6@1+ (1,0) [0|63] ""  Autopilot
 SG_ ProbClass : 48|5@1+ (3.125,0) [0|96.875] "%"  Autopilot
 SG_ Class : 53|3@1+ (1,0) [0|7] ""  Autopilot
 SG_ dxRearEndLoss : 56|6@1+ (1,0) [0|63] ""  Autopilot
 SG_ NotUsed : 62|1@1+ (1,0) [0|1] ""  Autopilot
 SG_ Index2 : 63|1@1+ (1,0) [0|1] ""  Autopilot

BO_ 1112 RadarPoint36_A: 8 Radar
 SG_ LongDist : 0|12@1+ (0.0625,0) [0|255.9] "meters"  Autopilot
 SG_ LongSpeed : 12|12@1+ (0.0625,-128) [-128|128] "meters/sec"  Autopilot
 SG_ LatDist : 24|11@1+ (0.125,-128) [-128|128] "meters"  Autopilot
 SG_ ProbExist : 35|5@1+ (3.125,0) [0|96.875] "%"  Autopilot
 SG_ LongAccel : 40|10@1+ (0.03125,-16) [-16|16] "meters/sec/sec"  Autopilot
 SG_ ProbObstacle : 50|5@1+ (3.125,0) [0|96.875] "%"  Autopilot
 SG_ Valid : 55|1@1+ (1,0) [0|1] ""  Autopilot
 SG_ ProbNonObstacle : 56|5@1+ (3.125,0) [0|96.875] "%"  Autopilot
 SG_ Meas : 61|1@1+ (1,0) [0|1] ""  Autopilot
 SG_ Tracked : 62|1@1+ (1,0) [0|1] ""  Autopilot
 SG_ Index : 63|1@1+ (1,0) [0|1] ""  Autopilot

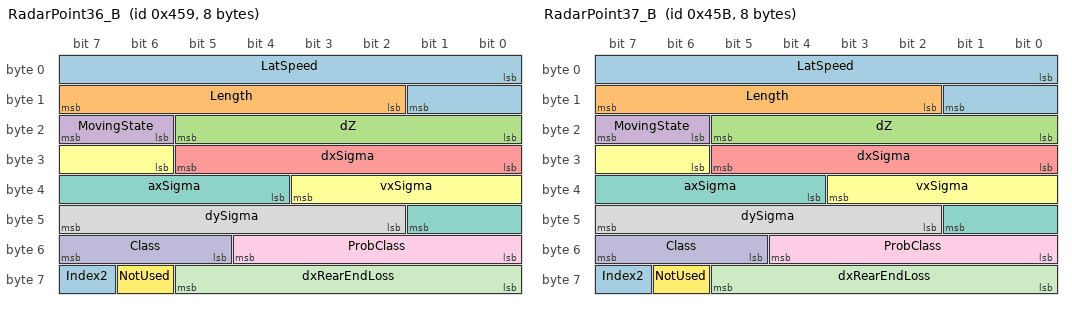
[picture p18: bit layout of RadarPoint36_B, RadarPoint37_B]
BO_ 1113 RadarPoint36_B: 8 Radar
 SG_ LatSpeed : 0|10@1+ (0.125,-64) [-64|64] "meters/sec"  Autopilot
 SG_ Length : 10|6@1+ (0.125,0) [0|7.875] "m"  Autopilot
 SG_ dZ : 16|6@1+ (0.25,-5) [-5|10.75] "m"  Autopilot
 SG_ MovingState : 22|2@1+ (1,0) [0|3] ""  Autopilot
 SG_ dxSigma : 24|6@1+ (1,0) [0|63] ""  Autopilot
 SG_ vxSigma : 30|6@1+ (1,0) [0|63] ""  Autopilot
 SG_ axSigma : 36|6@1+ (1,0) [0|63] ""  Autopilot
 SG_ dySigma : 42|6@1+ (1,0) [0|63] ""  Autopilot
 SG_ ProbClass : 48|5@1+ (3.125,0) [0|96.875] "%"  Autopilot
 SG_ Class : 53|3@1+ (1,0) [0|7] ""  Autopilot
 SG_ dxRearEndLoss : 56|6@1+ (1,0) [0|63] ""  Autopilot
 SG_ NotUsed : 62|1@1+ (1,0) [0|1] ""  Autopilot
 SG_ Index2 : 63|1@1+ (1,0) [0|1] ""  Autopilot

BO_ 1114 RadarPoint37_A: 8 Radar
 SG_ LongDist : 0|12@1+ (0.0625,0) [0|255.9] "meters"  Autopilot
 SG_ LongSpeed : 12|12@1+ (0.0625,-128) [-128|128] "meters/sec"  Autopilot
 SG_ LatDist : 24|11@1+ (0.125,-128) [-128|128] "meters"  Autopilot
 SG_ ProbExist : 35|5@1+ (3.125,0) [0|96.875] "%"  Autopilot
 SG_ LongAccel : 40|10@1+ (0.03125,-16) [-16|16] "meters/sec/sec"  Autopilot
 SG_ ProbObstacle : 50|5@1+ (3.125,0) [0|96.875] "%"  Autopilot
 SG_ Valid : 55|1@1+ (1,0) [0|1] ""  Autopilot
 SG_ ProbNonObstacle : 56|5@1+ (3.125,0) [0|96.875] "%"  Autopilot
 SG_ Meas : 61|1@1+ (1,0) [0|1] ""  Autopilot
 SG_ Tracked : 62|1@1+ (1,0) [0|1] ""  Autopilot
 SG_ Index : 63|1@1+ (1,0) [0|1] ""  Autopilot

BO_ 1115 RadarPoint37_B: 8 Radar
 SG_ LatSpeed : 0|10@1+ (0.125,-64) [-64|64] "meters/sec"  Autopilot
 SG_ Length : 10|6@1+ (0.125,0) [0|7.875] "m"  Autopilot
 SG_ dZ : 16|6@1+ (0.25,-5) [-5|10.75] "m"  Autopilot
 SG_ MovingState : 22|2@1+ (1,0) [0|3] ""  Autopilot
 SG_ dxSigma : 24|6@1+ (1,0) [0|63] ""  Autopilot
 SG_ vxSigma : 30|6@1+ (1,0) [0|63] ""  Autopilot
 SG_ axSigma : 36|6@1+ (1,0) [0|63] ""  Autopilot
 SG_ dySigma : 42|6@1+ (1,0) [0|63] ""  Autopilot
 SG_ ProbClass : 48|5@1+ (3.125,0) [0|96.875] "%"  Autopilot
 SG_ Class : 53|3@1+ (1,0) [0|7] ""  Autopilot
 SG_ dxRearEndLoss : 56|6@1+ (1,0) [0|63] ""  Autopilot
 SG_ NotUsed : 62|1@1+ (1,0) [0|1] ""  Autopilot
 SG_ Index2 : 63|1@1+ (1,0) [0|1] ""  Autopilot

BO_ 1116 RadarPoint38_A: 8 Radar
 SG_ LongDist : 0|12@1+ (0.0625,0) [0|255.9] "meters"  Autopilot
 SG_ LongSpeed : 12|12@1+ (0.0625,-128) [-128|128] "meters/sec"  Autopilot
 SG_ LatDist : 24|11@1+ (0.125,-128) [-128|128] "meters"  Autopilot
 SG_ ProbExist : 35|5@1+ (3.125,0) [0|96.875] "%"  Autopilot
 SG_ LongAccel : 40|10@1+ (0.03125,-16) [-16|16] "meters/sec/sec"  Autopilot
 SG_ ProbObstacle : 50|5@1+ (3.125,0) [0|96.875] "%"  Autopilot
 SG_ Valid : 55|1@1+ (1,0) [0|1] ""  Autopilot
 SG_ ProbNonObstacle : 56|5@1+ (3.125,0) [0|96.875] "%"  Autopilot
 SG_ Meas : 61|1@1+ (1,0) [0|1] ""  Autopilot
 SG_ Tracked : 62|1@1+ (1,0) [0|1] ""  Autopilot
 SG_ Index : 63|1@1+ (1,0) [0|1] ""  Autopilot

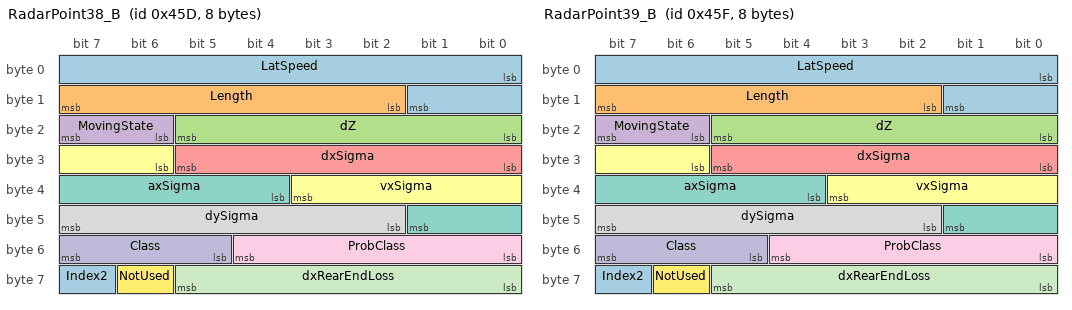
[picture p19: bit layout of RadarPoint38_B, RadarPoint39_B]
BO_ 1117 RadarPoint38_B: 8 Radar
 SG_ LatSpeed : 0|10@1+ (0.125,-64) [-64|64] "meters/sec"  Autopilot
 SG_ Length : 10|6@1+ (0.125,0) [0|7.875] "m"  Autopilot
 SG_ dZ : 16|6@1+ (0.25,-5) [-5|10.75] "m"  Autopilot
 SG_ MovingState : 22|2@1+ (1,0) [0|3] ""  Autopilot
 SG_ dxSigma : 24|6@1+ (1,0) [0|63] ""  Autopilot
 SG_ vxSigma : 30|6@1+ (1,0) [0|63] ""  Autopilot
 SG_ axSigma : 36|6@1+ (1,0) [0|63] ""  Autopilot
 SG_ dySigma : 42|6@1+ (1,0) [0|63] ""  Autopilot
 SG_ ProbClass : 48|5@1+ (3.125,0) [0|96.875] "%"  Autopilot
 SG_ Class : 53|3@1+ (1,0) [0|7] ""  Autopilot
 SG_ dxRearEndLoss : 56|6@1+ (1,0) [0|63] ""  Autopilot
 SG_ NotUsed : 62|1@1+ (1,0) [0|1] ""  Autopilot
 SG_ Index2 : 63|1@1+ (1,0) [0|1] ""  Autopilot

BO_ 1118 RadarPoint39_A: 8 Radar
 SG_ LongDist : 0|12@1+ (0.0625,0) [0|255.9] "meters"  Autopilot
 SG_ LongSpeed : 12|12@1+ (0.0625,-128) [-128|128] "meters/sec"  Autopilot
 SG_ LatDist : 24|11@1+ (0.125,-128) [-128|128] "meters"  Autopilot
 SG_ ProbExist : 35|5@1+ (3.125,0) [0|96.875] "%"  Autopilot
 SG_ LongAccel : 40|10@1+ (0.03125,-16) [-16|16] "meters/sec/sec"  Autopilot
 SG_ ProbObstacle : 50|5@1+ (3.125,0) [0|96.875] "%"  Autopilot
 SG_ Valid : 55|1@1+ (1,0) [0|1] ""  Autopilot
 SG_ ProbNonObstacle : 56|5@1+ (3.125,0) [0|96.875] "%"  Autopilot
 SG_ Meas : 61|1@1+ (1,0) [0|1] ""  Autopilot
 SG_ Tracked : 62|1@1+ (1,0) [0|1] ""  Autopilot
 SG_ Index : 63|1@1+ (1,0) [0|1] ""  Autopilot

BO_ 1119 RadarPoint39_B: 8 Radar
 SG_ LatSpeed : 0|10@1+ (0.125,-64) [-64|64] "meters/sec"  Autopilot
 SG_ Length : 10|6@1+ (0.125,0) [0|7.875] "m"  Autopilot
 SG_ dZ : 16|6@1+ (0.25,-5) [-5|10.75] "m"  Autopilot
 SG_ MovingState : 22|2@1+ (1,0) [0|3] ""  Autopilot
 SG_ dxSigma : 24|6@1+ (1,0) [0|63] ""  Autopilot
 SG_ vxSigma : 30|6@1+ (1,0) [0|63] ""  Autopilot
 SG_ axSigma : 36|6@1+ (1,0) [0|63] ""  Autopilot
 SG_ dySigma : 42|6@1+ (1,0) [0|63] ""  Autopilot
 SG_ ProbClass : 48|5@1+ (3.125,0) [0|96.875] "%"  Autopilot
 SG_ Class : 53|3@1+ (1,0) [0|7] ""  Autopilot
 SG_ dxRearEndLoss : 56|6@1+ (1,0) [0|63] ""  Autopilot
 SG_ NotUsed : 62|1@1+ (1,0) [0|1] ""  Autopilot
 SG_ Index2 : 63|1@1+ (1,0) [0|1] ""  Autopilot

VAL_ 1025 lowPowerMode 1 "COMMANDED_LOW_POWER" 0 "DEFAULT_LOW_POWER" 2 "NORMAL_POWER" 3 "SNA";
VAL_ 1041 MovingState 3 "RADAR_MOVESTATE_STANDING" 2 "RADAR_MOVESTATE_STOPPED" 1 "RADAR_MOVESTATE_MOVING" 0 "RADAR_MOVESTATE_INDETERMINATE" ;
VAL_ 1041 Class 4 "RADAR_CLASS_CONSTRUCTION_ELEMENT" 3 "RADAR_CLASS_MOVING_PEDESTRIAN" 2 "RADAR_CLASS_MOVING_TWO_WHEEL_VEHICLE" 1 "RADAR_CLASS_MOVING_FOUR_WHEEL_VEHICLE" 0 "RADAR_CLASS_UNKNOWN" ;
VAL_ 1043 MovingState 3 "RADAR_MOVESTATE_STANDING" 2 "RADAR_MOVESTATE_STOPPED" 1 "RADAR_MOVESTATE_MOVING" 0 "RADAR_MOVESTATE_INDETERMINATE" ;
VAL_ 1043 Class 4 "RADAR_CLASS_CONSTRUCTION_ELEMENT" 3 "RADAR_CLASS_MOVING_PEDESTRIAN" 2 "RADAR_CLASS_MOVING_TWO_WHEEL_VEHICLE" 1 "RADAR_CLASS_MOVING_FOUR_WHEEL_VEHICLE" 0 "RADAR_CLASS_UNKNOWN" ;
VAL_ 1045 MovingState 3 "RADAR_MOVESTATE_STANDING" 2 "RADAR_MOVESTATE_STOPPED" 1 "RADAR_MOVESTATE_MOVING" 0 "RADAR_MOVESTATE_INDETERMINATE" ;
VAL_ 1045 Class 4 "RADAR_CLASS_CONSTRUCTION_ELEMENT" 3 "RADAR_CLASS_MOVING_PEDESTRIAN" 2 "RADAR_CLASS_MOVING_TWO_WHEEL_VEHICLE" 1 "RADAR_CLASS_MOVING_FOUR_WHEEL_VEHICLE" 0 "RADAR_CLASS_UNKNOWN" ;
VAL_ 1047 MovingState 3 "RADAR_MOVESTATE_STANDING" 2 "RADAR_MOVESTATE_STOPPED" 1 "RADAR_MOVESTATE_MOVING" 0 "RADAR_MOVESTATE_INDETERMINATE" ;
VAL_ 1047 Class 4 "RADAR_CLASS_CONSTRUCTION_ELEMENT" 3 "RADAR_CLASS_MOVING_PEDESTRIAN" 2 "RADAR_CLASS_MOVING_TWO_WHEEL_VEHICLE" 1 "RADAR_CLASS_MOVING_FOUR_WHEEL_VEHICLE" 0 "RADAR_CLASS_UNKNOWN" ;
VAL_ 1049 MovingState 3 "RADAR_MOVESTATE_STANDING" 2 "RADAR_MOVESTATE_STOPPED" 1 "RADAR_MOVESTATE_MOVING" 0 "RADAR_MOVESTATE_INDETERMINATE" ;
VAL_ 1049 Class 4 "RADAR_CLASS_CONSTRUCTION_ELEMENT" 3 "RADAR_CLASS_MOVING_PEDESTRIAN" 2 "RADAR_CLASS_MOVING_TWO_WHEEL_VEHICLE" 1 "RADAR_CLASS_MOVING_FOUR_WHEEL_VEHICLE" 0 "RADAR_CLASS_UNKNOWN" ;
VAL_ 1051 MovingState 3 "RADAR_MOVESTATE_STANDING" 2 "RADAR_MOVESTATE_STOPPED" 1 "RADAR_MOVESTATE_MOVING" 0 "RADAR_MOVESTATE_INDETERMINATE" ;
VAL_ 1051 Class 4 "RADAR_CLASS_CONSTRUCTION_ELEMENT" 3 "RADAR_CLASS_MOVING_PEDESTRIAN" 2 "RADAR_CLASS_MOVING_TWO_WHEEL_VEHICLE" 1 "RADAR_CLASS_MOVING_FOUR_WHEEL_VEHICLE" 0 "RADAR_CLASS_UNKNOWN" ;
VAL_ 1053 MovingState 3 "RADAR_MOVESTATE_STANDING" 2 "RADAR_MOVESTATE_STOPPED" 1 "RADAR_MOVESTATE_MOVING" 0 "RADAR_MOVESTATE_INDETERMINATE" ;
VAL_ 1053 Class 4 "RADAR_CLASS_CONSTRUCTION_ELEMENT" 3 "RADAR_CLASS_MOVING_PEDESTRIAN" 2 "RADAR_CLASS_MOVING_TWO_WHEEL_VEHICLE" 1 "RADAR_CLASS_MOVING_FOUR_WHEEL_VEHICLE" 0 "RADAR_CLASS_UNKNOWN" ;
VAL_ 1055 MovingState 3 "RADAR_MOVESTATE_STANDING" 2 "RADAR_MOVESTATE_STOPPED" 1 "RADAR_MOVESTATE_MOVING" 0 "RADAR_MOVESTATE_INDETERMINATE" ;
VAL_ 1055 Class 4 "RADAR_CLASS_CONSTRUCTION_ELEMENT" 3 "RADAR_CLASS_MOVING_PEDESTRIAN" 2 "RADAR_CLASS_MOVING_TWO_WHEEL_VEHICLE" 1 "RADAR_CLASS_MOVING_FOUR_WHEEL_VEHICLE" 0 "RADAR_CLASS_UNKNOWN" ;
VAL_ 1057 MovingState 3 "RADAR_MOVESTATE_STANDING" 2 "RADAR_MOVESTATE_STOPPED" 1 "RADAR_MOVESTATE_MOVING" 0 "RADAR_MOVESTATE_INDETERMINATE" ;
VAL_ 1057 Class 4 "RADAR_CLASS_CONSTRUCTION_ELEMENT" 3 "RADAR_CLASS_MOVING_PEDESTRIAN" 2 "RADAR_CLASS_MOVING_TWO_WHEEL_VEHICLE" 1 "RADAR_CLASS_MOVING_FOUR_WHEEL_VEHICLE" 0 "RADAR_CLASS_UNKNOWN" ;
VAL_ 1059 MovingState 3 "RADAR_MOVESTATE_STANDING" 2 "RADAR_MOVESTATE_STOPPED" 1 "RADAR_MOVESTATE_MOVING" 0 "RADAR_MOVESTATE_INDETERMINATE" ;
VAL_ 1059 Class 4 "RADAR_CLASS_CONSTRUCTION_ELEMENT" 3 "RADAR_CLASS_MOVING_PEDESTRIAN" 2 "RADAR_CLASS_MOVING_TWO_WHEEL_VEHICLE" 1 "RADAR_CLASS_MOVING_FOUR_WHEEL_VEHICLE" 0 "RADAR_CLASS_UNKNOWN" ;
VAL_ 1061 MovingState 3 "RADAR_MOVESTATE_STANDING" 2 "RADAR_MOVESTATE_STOPPED" 1 "RADAR_MOVESTATE_MOVING" 0 "RADAR_MOVESTATE_INDETERMINATE" ;
VAL_ 1061 Class 4 "RADAR_CLASS_CONSTRUCTION_ELEMENT" 3 "RADAR_CLASS_MOVING_PEDESTRIAN" 2 "RADAR_CLASS_MOVING_TWO_WHEEL_VEHICLE" 1 "RADAR_CLASS_MOVING_FOUR_WHEEL_VEHICLE" 0 "RADAR_CLASS_UNKNOWN" ;
VAL_ 1063 MovingState 3 "RADAR_MOVESTATE_STANDING" 2 "RADAR_MOVESTATE_STOPPED" 1 "RADAR_MOVESTATE_MOVING" 0 "RADAR_MOVESTATE_INDETERMINATE" ;
VAL_ 1063 Class 4 "RADAR_CLASS_CONSTRUCTION_ELEMENT" 3 "RADAR_CLASS_MOVING_PEDESTRIAN" 2 "RADAR_CLASS_MOVING_TWO_WHEEL_VEHICLE" 1 "RADAR_CLASS_MOVING_FOUR_WHEEL_VEHICLE" 0 "RADAR_CLASS_UNKNOWN" ;
VAL_ 1065 MovingState 3 "RADAR_MOVESTATE_STANDING" 2 "RADAR_MOVESTATE_STOPPED" 1 "RADAR_MOVESTATE_MOVING" 0 "RADAR_MOVESTATE_INDETERMINATE" ;
VAL_ 1065 Class 4 "RADAR_CLASS_CONSTRUCTION_ELEMENT" 3 "RADAR_CLASS_MOVING_PEDESTRIAN" 2 "RADAR_CLASS_MOVING_TWO_WHEEL_VEHICLE" 1 "RADAR_CLASS_MOVING_FOUR_WHEEL_VEHICLE" 0 "RADAR_CLASS_UNKNOWN" ;
VAL_ 1067 MovingState 3 "RADAR_MOVESTATE_STANDING" 2 "RADAR_MOVESTATE_STOPPED" 1 "RADAR_MOVESTATE_MOVING" 0 "RADAR_MOVESTATE_INDETERMINATE" ;
VAL_ 1067 Class 4 "RADAR_CLASS_CONSTRUCTION_ELEMENT" 3 "RADAR_CLASS_MOVING_PEDESTRIAN" 2 "RADAR_CLASS_MOVING_TWO_WHEEL_VEHICLE" 1 "RADAR_CLASS_MOVING_FOUR_WHEEL_VEHICLE" 0 "RADAR_CLASS_UNKNOWN" ;
VAL_ 1069 MovingState 3 "RADAR_MOVESTATE_STANDING" 2 "RADAR_MOVESTATE_STOPPED" 1 "RADAR_MOVESTATE_MOVING" 0 "RADAR_MOVESTATE_INDETERMINATE" ;
VAL_ 1069 Class 4 "RADAR_CLASS_CONSTRUCTION_ELEMENT" 3 "RADAR_CLASS_MOVING_PEDESTRIAN" 2 "RADAR_CLASS_MOVING_TWO_WHEEL_VEHICLE" 1 "RADAR_CLASS_MOVING_FOUR_WHEEL_VEHICLE" 0 "RADAR_CLASS_UNKNOWN" ;
VAL_ 1071 MovingState 3 "RADAR_MOVESTATE_STANDING" 2 "RADAR_MOVESTATE_STOPPED" 1 "RADAR_MOVESTATE_MOVING" 0 "RADAR_MOVESTATE_INDETERMINATE" ;
VAL_ 1071 Class 4 "RADAR_CLASS_CONSTRUCTION_ELEMENT" 3 "RADAR_CLASS_MOVING_PEDESTRIAN" 2 "RADAR_CLASS_MOVING_TWO_WHEEL_VEHICLE" 1 "RADAR_CLASS_MOVING_FOUR_WHEEL_VEHICLE" 0 "RADAR_CLASS_UNKNOWN" ;
VAL_ 1073 MovingState 3 "RADAR_MOVESTATE_STANDING" 2 "RADAR_MOVESTATE_STOPPED" 1 "RADAR_MOVESTATE_MOVING" 0 "RADAR_MOVESTATE_INDETERMINATE" ;
VAL_ 1073 Class 4 "RADAR_CLASS_CONSTRUCTION_ELEMENT" 3 "RADAR_CLASS_MOVING_PEDESTRIAN" 2 "RADAR_CLASS_MOVING_TWO_WHEEL_VEHICLE" 1 "RADAR_CLASS_MOVING_FOUR_WHEEL_VEHICLE" 0 "RADAR_CLASS_UNKNOWN" ;
VAL_ 1075 MovingState 3 "RADAR_MOVESTATE_STANDING" 2 "RADAR_MOVESTATE_STOPPED" 1 "RADAR_MOVESTATE_MOVING" 0 "RADAR_MOVESTATE_INDETERMINATE" ;
VAL_ 1075 Class 4 "RADAR_CLASS_CONSTRUCTION_ELEMENT" 3 "RADAR_CLASS_MOVING_PEDESTRIAN" 2 "RADAR_CLASS_MOVING_TWO_WHEEL_VEHICLE" 1 "RADAR_CLASS_MOVING_FOUR_WHEEL_VEHICLE" 0 "RADAR_CLASS_UNKNOWN" ;
VAL_ 1077 MovingState 3 "RADAR_MOVESTATE_STANDING" 2 "RADAR_MOVESTATE_STOPPED" 1 "RADAR_MOVESTATE_MOVING" 0 "RADAR_MOVESTATE_INDETERMINATE" ;
VAL_ 1077 Class 4 "RADAR_CLASS_CONSTRUCTION_ELEMENT" 3 "RADAR_CLASS_MOVING_PEDESTRIAN" 2 "RADAR_CLASS_MOVING_TWO_WHEEL_VEHICLE" 1 "RADAR_CLASS_MOVING_FOUR_WHEEL_VEHICLE" 0 "RADAR_CLASS_UNKNOWN" ;
VAL_ 1079 MovingState 3 "RADAR_MOVESTATE_STANDING" 2 "RADAR_MOVESTATE_STOPPED" 1 "RADAR_MOVESTATE_MOVING" 0 "RADAR_MOVESTATE_INDETERMINATE" ;
VAL_ 1079 Class 4 "RADAR_CLASS_CONSTRUCTION_ELEMENT" 3 "RADAR_CLASS_MOVING_PEDESTRIAN" 2 "RADAR_CLASS_MOVING_TWO_WHEEL_VEHICLE" 1 "RADAR_CLASS_MOVING_FOUR_WHEEL_VEHICLE" 0 "RADAR_CLASS_UNKNOWN" ;
VAL_ 1081 MovingState 3 "RADAR_MOVESTATE_STANDING" 2 "RADAR_MOVESTATE_STOPPED" 1 "RADAR_MOVESTATE_MOVING" 0 "RADAR_MOVESTATE_INDETERMINATE" ;
VAL_ 1081 Class 4 "RADAR_CLASS_CONSTRUCTION_ELEMENT" 3 "RADAR_CLASS_MOVING_PEDESTRIAN" 2 "RADAR_CLASS_MOVING_TWO_WHEEL_VEHICLE" 1 "RADAR_CLASS_MOVING_FOUR_WHEEL_VEHICLE" 0 "RADAR_CLASS_UNKNOWN" ;
VAL_ 1083 MovingState 3 "RADAR_MOVESTATE_STANDING" 2 "RADAR_MOVESTATE_STOPPED" 1 "RADAR_MOVESTATE_MOVING" 0 "RADAR_MOVESTATE_INDETERMINATE" ;
VAL_ 1083 Class 4 "RADAR_CLASS_CONSTRUCTION_ELEMENT" 3 "RADAR_CLASS_MOVING_PEDESTRIAN" 2 "RADAR_CLASS_MOVING_TWO_WHEEL_VEHICLE" 1 "RADAR_CLASS_MOVING_FOUR_WHEEL_VEHICLE" 0 "RADAR_CLASS_UNKNOWN" ;
VAL_ 1085 MovingState 3 "RADAR_MOVESTATE_STANDING" 2 "RADAR_MOVESTATE_STOPPED" 1 "RADAR_MOVESTATE_MOVING" 0 "RADAR_MOVESTATE_INDETERMINATE" ;
VAL_ 1085 Class 4 "RADAR_CLASS_CONSTRUCTION_ELEMENT" 3 "RADAR_CLASS_MOVING_PEDESTRIAN" 2 "RADAR_CLASS_MOVING_TWO_WHEEL_VEHICLE" 1 "RADAR_CLASS_MOVING_FOUR_WHEEL_VEHICLE" 0 "RADAR_CLASS_UNKNOWN" ;
VAL_ 1087 MovingState 3 "RADAR_MOVESTATE_STANDING" 2 "RADAR_MOVESTATE_STOPPED" 1 "RADAR_MOVESTATE_MOVING" 0 "RADAR_MOVESTATE_INDETERMINATE" ;
VAL_ 1087 Class 4 "RADAR_CLASS_CONSTRUCTION_ELEMENT" 3 "RADAR_CLASS_MOVING_PEDESTRIAN" 2 "RADAR_CLASS_MOVING_TWO_WHEEL_VEHICLE" 1 "RADAR_CLASS_MOVING_FOUR_WHEEL_VEHICLE" 0 "RADAR_CLASS_UNKNOWN" ;
VAL_ 1089 MovingState 3 "RADAR_MOVESTATE_STANDING" 2 "RADAR_MOVESTATE_STOPPED" 1 "RADAR_MOVESTATE_MOVING" 0 "RADAR_MOVESTATE_INDETERMINATE" ;
VAL_ 1089 Class 4 "RADAR_CLASS_CONSTRUCTION_ELEMENT" 3 "RADAR_CLASS_MOVING_PEDESTRIAN" 2 "RADAR_CLASS_MOVING_TWO_WHEEL_VEHICLE" 1 "RADAR_CLASS_MOVING_FOUR_WHEEL_VEHICLE" 0 "RADAR_CLASS_UNKNOWN" ;
VAL_ 1091 MovingState 3 "RADAR_MOVESTATE_STANDING" 2 "RADAR_MOVESTATE_STOPPED" 1 "RADAR_MOVESTATE_MOVING" 0 "RADAR_MOVESTATE_INDETERMINATE" ;
VAL_ 1091 Class 4 "RADAR_CLASS_CONSTRUCTION_ELEMENT" 3 "RADAR_CLASS_MOVING_PEDESTRIAN" 2 "RADAR_CLASS_MOVING_TWO_WHEEL_VEHICLE" 1 "RADAR_CLASS_MOVING_FOUR_WHEEL_VEHICLE" 0 "RADAR_CLASS_UNKNOWN" ;
VAL_ 1093 MovingState 3 "RADAR_MOVESTATE_STANDING" 2 "RADAR_MOVESTATE_STOPPED" 1 "RADAR_MOVESTATE_MOVING" 0 "RADAR_MOVESTATE_INDETERMINATE" ;
VAL_ 1093 Class 4 "RADAR_CLASS_CONSTRUCTION_ELEMENT" 3 "RADAR_CLASS_MOVING_PEDESTRIAN" 2 "RADAR_CLASS_MOVING_TWO_WHEEL_VEHICLE" 1 "RADAR_CLASS_MOVING_FOUR_WHEEL_VEHICLE" 0 "RADAR_CLASS_UNKNOWN" ;
VAL_ 1095 MovingState 3 "RADAR_MOVESTATE_STANDING" 2 "RADAR_MOVESTATE_STOPPED" 1 "RADAR_MOVESTATE_MOVING" 0 "RADAR_MOVESTATE_INDETERMINATE" ;
VAL_ 1095 Class 4 "RADAR_CLASS_CONSTRUCTION_ELEMENT" 3 "RADAR_CLASS_MOVING_PEDESTRIAN" 2 "RADAR_CLASS_MOVING_TWO_WHEEL_VEHICLE" 1 "RADAR_CLASS_MOVING_FOUR_WHEEL_VEHICLE" 0 "RADAR_CLASS_UNKNOWN" ;
VAL_ 1097 MovingState 3 "RADAR_MOVESTATE_STANDING" 2 "RADAR_MOVESTATE_STOPPED" 1 "RADAR_MOVESTATE_MOVING" 0 "RADAR_MOVESTATE_INDETERMINATE" ;
VAL_ 1097 Class 4 "RADAR_CLASS_CONSTRUCTION_ELEMENT" 3 "RADAR_CLASS_MOVING_PEDESTRIAN" 2 "RADAR_CLASS_MOVING_TWO_WHEEL_VEHICLE" 1 "RADAR_CLASS_MOVING_FOUR_WHEEL_VEHICLE" 0 "RADAR_CLASS_UNKNOWN" ;
VAL_ 1099 MovingState 3 "RADAR_MOVESTATE_STANDING" 2 "RADAR_MOVESTATE_STOPPED" 1 "RADAR_MOVESTATE_MOVING" 0 "RADAR_MOVESTATE_INDETERMINATE" ;
VAL_ 1099 Class 4 "RADAR_CLASS_CONSTRUCTION_ELEMENT" 3 "RADAR_CLASS_MOVING_PEDESTRIAN" 2 "RADAR_CLASS_MOVING_TWO_WHEEL_VEHICLE" 1 "RADAR_CLASS_MOVING_FOUR_WHEEL_VEHICLE" 0 "RADAR_CLASS_UNKNOWN" ;
VAL_ 1101 MovingState 3 "RADAR_MOVESTATE_STANDING" 2 "RADAR_MOVESTATE_STOPPED" 1 "RADAR_MOVESTATE_MOVING" 0 "RADAR_MOVESTATE_INDETERMINATE" ;
VAL_ 1101 Class 4 "RADAR_CLASS_CONSTRUCTION_ELEMENT" 3 "RADAR_CLASS_MOVING_PEDESTRIAN" 2 "RADAR_CLASS_MOVING_TWO_WHEEL_VEHICLE" 1 "RADAR_CLASS_MOVING_FOUR_WHEEL_VEHICLE" 0 "RADAR_CLASS_UNKNOWN" ;
VAL_ 1103 MovingState 3 "RADAR_MOVESTATE_STANDING" 2 "RADAR_MOVESTATE_STOPPED" 1 "RADAR_MOVESTATE_MOVING" 0 "RADAR_MOVESTATE_INDETERMINATE" ;
VAL_ 1103 Class 4 "RADAR_CLASS_CONSTRUCTION_ELEMENT" 3 "RADAR_CLASS_MOVING_PEDESTRIAN" 2 "RADAR_CLASS_MOVING_TWO_WHEEL_VEHICLE" 1 "RADAR_CLASS_MOVING_FOUR_WHEEL_VEHICLE" 0 "RADAR_CLASS_UNKNOWN" ;
VAL_ 1105 MovingState 3 "RADAR_MOVESTATE_STANDING" 2 "RADAR_MOVESTATE_STOPPED" 1 "RADAR_MOVESTATE_MOVING" 0 "RADAR_MOVESTATE_INDETERMINATE" ;
VAL_ 1105 Class 4 "RADAR_CLASS_CONSTRUCTION_ELEMENT" 3 "RADAR_CLASS_MOVING_PEDESTRIAN" 2 "RADAR_CLASS_MOVING_TWO_WHEEL_VEHICLE" 1 "RADAR_CLASS_MOVING_FOUR_WHEEL_VEHICLE" 0 "RADAR_CLASS_UNKNOWN" ;
VAL_ 1107 MovingState 3 "RADAR_MOVESTATE_STANDING" 2 "RADAR_MOVESTATE_STOPPED" 1 "RADAR_MOVESTATE_MOVING" 0 "RADAR_MOVESTATE_INDETERMINATE" ;
VAL_ 1107 Class 4 "RADAR_CLASS_CONSTRUCTION_ELEMENT" 3 "RADAR_CLASS_MOVING_PEDESTRIAN" 2 "RADAR_CLASS_MOVING_TWO_WHEEL_VEHICLE" 1 "RADAR_CLASS_MOVING_FOUR_WHEEL_VEHICLE" 0 "RADAR_CLASS_UNKNOWN" ;
VAL_ 1109 MovingState 3 "RADAR_MOVESTATE_STANDING" 2 "RADAR_MOVESTATE_STOPPED" 1 "RADAR_MOVESTATE_MOVING" 0 "RADAR_MOVESTATE_INDETERMINATE" ;
VAL_ 1109 Class 4 "RADAR_CLASS_CONSTRUCTION_ELEMENT" 3 "RADAR_CLASS_MOVING_PEDESTRIAN" 2 "RADAR_CLASS_MOVING_TWO_WHEEL_VEHICLE" 1 "RADAR_CLASS_MOVING_FOUR_WHEEL_VEHICLE" 0 "RADAR_CLASS_UNKNOWN" ;
VAL_ 1111 MovingState 3 "RADAR_MOVESTATE_STANDING" 2 "RADAR_MOVESTATE_STOPPED" 1 "RADAR_MOVESTATE_MOVING" 0 "RADAR_MOVESTATE_INDETERMINATE" ;
VAL_ 1111 Class 4 "RADAR_CLASS_CONSTRUCTION_ELEMENT" 3 "RADAR_CLASS_MOVING_PEDESTRIAN" 2 "RADAR_CLASS_MOVING_TWO_WHEEL_VEHICLE" 1 "RADAR_CLASS_MOVING_FOUR_WHEEL_VEHICLE" 0 "RADAR_CLASS_UNKNOWN" ;
VAL_ 1113 MovingState 3 "RADAR_MOVESTATE_STANDING" 2 "RADAR_MOVESTATE_STOPPED" 1 "RADAR_MOVESTATE_MOVING" 0 "RADAR_MOVESTATE_INDETERMINATE" ;
VAL_ 1113 Class 4 "RADAR_CLASS_CONSTRUCTION_ELEMENT" 3 "RADAR_CLASS_MOVING_PEDESTRIAN" 2 "RADAR_CLASS_MOVING_TWO_WHEEL_VEHICLE" 1 "RADAR_CLASS_MOVING_FOUR_WHEEL_VEHICLE" 0 "RADAR_CLASS_UNKNOWN" ;
VAL_ 1115 MovingState 3 "RADAR_MOVESTATE_STANDING" 2 "RADAR_MOVESTATE_STOPPED" 1 "RADAR_MOVESTATE_MOVING" 0 "RADAR_MOVESTATE_INDETERMINATE" ;
VAL_ 1115 Class 4 "RADAR_CLASS_CONSTRUCTION_ELEMENT" 3 "RADAR_CLASS_MOVING_PEDESTRIAN" 2 "RADAR_CLASS_MOVING_TWO_WHEEL_VEHICLE" 1 "RADAR_CLASS_MOVING_FOUR_WHEEL_VEHICLE" 0 "RADAR_CLASS_UNKNOWN" ;
VAL_ 1117 MovingState 3 "RADAR_MOVESTATE_STANDING" 2 "RADAR_MOVESTATE_STOPPED" 1 "RADAR_MOVESTATE_MOVING" 0 "RADAR_MOVESTATE_INDETERMINATE" ;
VAL_ 1117 Class 4 "RADAR_CLASS_CONSTRUCTION_ELEMENT" 3 "RADAR_CLASS_MOVING_PEDESTRIAN" 2 "RADAR_CLASS_MOVING_TWO_WHEEL_VEHICLE" 1 "RADAR_CLASS_MOVING_FOUR_WHEEL_VEHICLE" 0 "RADAR_CLASS_UNKNOWN" ;
VAL_ 1119 MovingState 3 "RADAR_MOVESTATE_STANDING" 2 "RADAR_MOVESTATE_STOPPED" 1 "RADAR_MOVESTATE_MOVING" 0 "RADAR_MOVESTATE_INDETERMINATE" ;
VAL_ 1119 Class 4 "RADAR_CLASS_CONSTRUCTION_ELEMENT" 3 "RADAR_CLASS_MOVING_PEDESTRIAN" 2 "RADAR_CLASS_MOVING_TWO_WHEEL_VEHICLE" 1 "RADAR_CLASS_MOVING_FOUR_WHEEL_VEHICLE" 0 "RADAR_CLASS_UNKNOWN" ;
